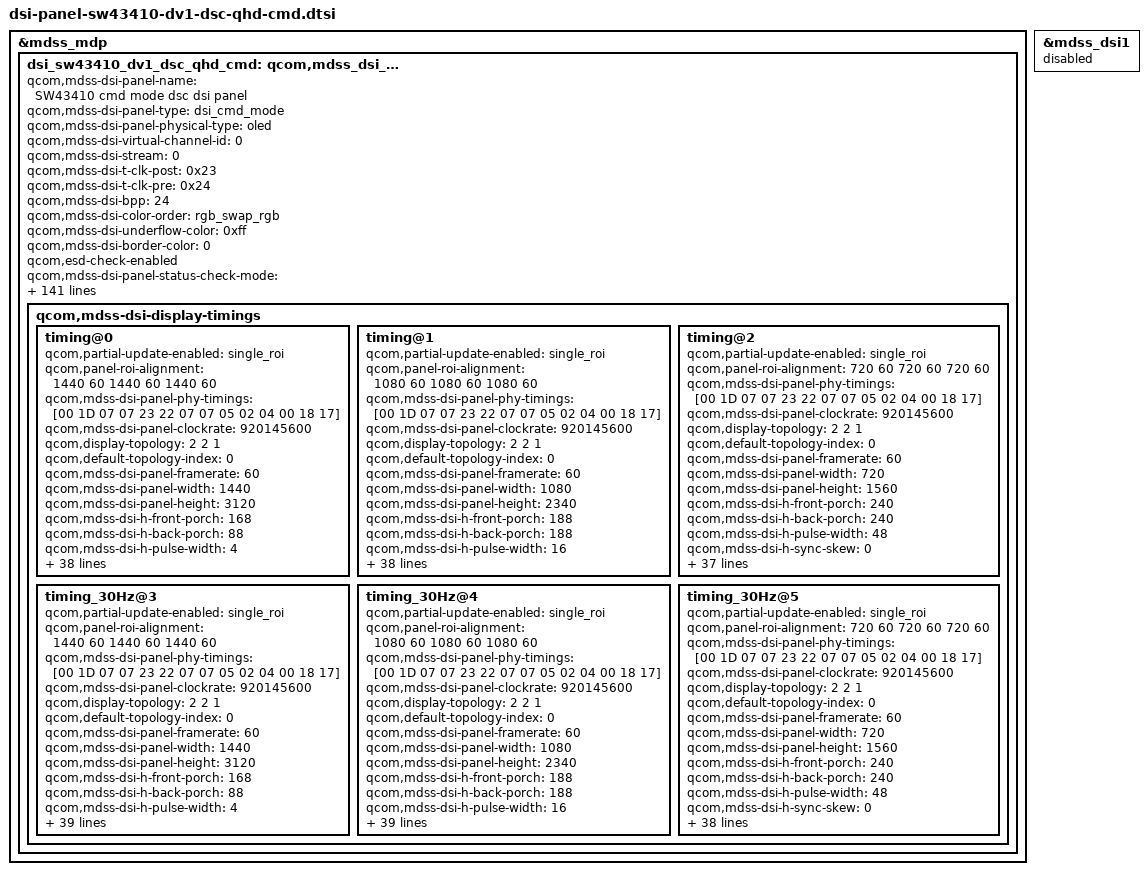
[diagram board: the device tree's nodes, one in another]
/* Copyright (c) 2014, Code Aurora Forum. All rights reserved.
 *
 * This program is free software; you can redistribute it and/or modify
 * it under the terms of the GNU General Public License version 2 and
 * only version 2 as published by the Free Software Foundation.
 *
 * This program is distributed in the hope that it will be useful,
 * but WITHOUT ANY WARRANTY; without even the implied warranty of
 * MERCHANTABILITY or FITNESS FOR A PARTICULAR PURPOSE.  See the
 * GNU General Public License for more details.
 */

&mdss_mdp {
    dsi_sw43410_dv1_dsc_qhd_cmd: qcom,mdss_dsi_sw43410_dv1_dsc_qhd_cmd {
        qcom,mdss-dsi-panel-name = "SW43410 cmd mode dsc dsi panel";
		qcom,mdss-dsi-panel-type = "dsi_cmd_mode";
		qcom,mdss-dsi-panel-physical-type = "oled";
		qcom,mdss-dsi-virtual-channel-id = <0>;
		qcom,mdss-dsi-stream = <0>;
		qcom,mdss-dsi-t-clk-post = <0x23>;
		qcom,mdss-dsi-t-clk-pre = <0x24>;
		qcom,mdss-dsi-bpp = <24>;
		qcom,mdss-dsi-color-order = "rgb_swap_rgb";
		qcom,mdss-dsi-underflow-color = <0xff>;
		qcom,mdss-dsi-border-color = <0>;
		qcom,esd-check-enabled;
		qcom,mdss-dsi-panel-status-check-mode = "te_signal_check";
		qcom,mdss-dsi-traffic-mode = "burst_mode";
		qcom,mdss-dsi-lane-map = "lane_map_0123";
		qcom,mdss-dsi-bllp-eof-power-mode;
		qcom,mdss-dsi-bllp-power-mode;
		qcom,mdss-dsi-lane-0-state;
		qcom,mdss-dsi-lane-1-state;
		qcom,mdss-dsi-lane-2-state;
		qcom,mdss-dsi-lane-3-state;
		qcom,mdss-dsi-reset-sequence = <1 10>, <0 2>, <1 10>;
		lge,mdss-iris3-reset-sequence = <1 20>, <0 20>, <1 20>;
		qcom,mdss-dsi-dma-trigger = "trigger_sw";
		qcom,mdss-dsi-mdp-trigger = "none";
		qcom,mdss-dsi-te-pin-select = <1>;
		qcom,mdss-dsi-wr-mem-start = <0x2c>;
		qcom,mdss-dsi-wr-mem-continue = <0x3c>;
		qcom,mdss-dsi-te-dcs-command = <1>;
		qcom,mdss-dsi-te-check-enable;
		qcom,mdss-dsi-te-using-te-pin;
		qcom,mdss-dsi-lp11-init;
		qcom,mdss-dsi-tx-eot-append;
		//qcom,ulps-enabled;
		//qcom,mdss-dsi-force-clock-lane-hs;

		qcom,mdss-dsi-panel-hdr-enabled;
		qcom,mdss-dsi-panel-hdr-color-primaries = <14880 15935 32435 16555 14945 30910 7790 3415>;
		qcom,mdss-dsi-panel-peak-brightness = <5643000>;		/* max. 500nits */
		qcom,mdss-dsi-panel-blackness-level = <6134>;
		qcom,dynamic-mode-switch-enabled;
		qcom,dynamic-mode-switch-type = "dynamic-resolution-switch-immediate";
		lge,drs-mngr-enabled;
		lge,drs-mngr-internal-pps-switch-enabled;
		lge,use-ambient;
		lge,aod-interface-data = "partial", "partial", "partial";

		lge,use-color-manager;
		lge,color-manager-default-status = <1>;
		lge,mdss-dsi-color-manager-mode-table = <3 1>, <0 1>, <2 1>, <1 1>;
		lge,true-view-supported;

		lge,mdss-dsi-wb-default-command = [
			15 00 00 00 00 00 02 B0 55
			39 00 00 00 00 00 21 EC 3F 03 01 56 AB FC 03 00 55 AA FC 03 00 55 AA FC 00 FF 40 80 C0 00 40 80 C0 00 40 80 C0 00 40 80
			39 00 00 00 00 00 21 ED C0 00 ED 3F 7E BD FB 3A 79 B8 F7 36 75 B4 F2 31 70 AF 00 D0 3D 7A B7 F4 31 6E AB E8 26 63 A0 DD
			39 00 00 00 00 00 04 EE 1A 57 94
			15 01 00 00 00 00 02 B0 CA
		];
		lge,mdss-dsi-wb-default-command-state = "dsi_hs_mode";

		lge,digital-gamma-cmds-dummy = [
			15 00 00 00 00 00 02 B0 55
			39 00 00 00 00 00 21 EC 3F 03 01 56 AB FC 03 00 55 AA FC 03 00 55 AA FC 00 FF 40 80 C0 00 40 80 C0 00 40 80 C0 00 40 80
			39 00 00 00 00 00 21 ED C0 00 ED 3F 7E BD FB 3A 79 B8 F7 36 75 B4 F2 31 70 AF 00 D0 3D 7A B7 F4 31 6E AB E8 26 63 A0 DD
			39 00 00 00 00 00 04 EE 1A 57 94
			15 01 00 00 00 00 02 B0 CA
		];
		lge,digital-gamma-cmds-dummy-command = "dsi_hs_mode";

		lge,mdss-dsi-disp-ctrl-command-1 = [
			39 01 00 00 00 00 03 53 0C 30
		];
		lge,mdss-dsi-disp-ctrl-command-1-state = "dsi_hs_mode";
		lge,mdss-dsi-disp-ctrl-command-2 = [
			39 01 00 00 00 00 04 55 16 29 C0
		];
		lge,mdss-dsi-disp-ctrl-command-2-state = "dsi_hs_mode";

		lge,digital-gamma-set = [
			39 01 00 00 00 00 21 EC 3F 03 01 56 AB FC 03 00 55 AA FC 03 00 55 AA FC 00 FF 40 80 C0 00 40 80 C0 00 40 80 C0 00 40 80
			39 01 00 00 00 00 21 ED C0 00 ED 3F 7E BD FB 3A 79 B8 F7 36 75 B4 F2 31 70 AF 00 D0 3D 7A B7 F4 31 6E AB E8 26 63 A0 DD
			39 01 00 00 00 00 04 EE 1A 57 94
			39 01 00 00 00 00 21 EC 3F 03 00 55 AA FC 03 00 55 AA FC 03 01 56 AB FC 00 EB 3F 7D BC FB 3A 78 B7 F6 35 73 B2 F1 30 6E
			39 01 00 00 00 00 21 ED AD 00 F0 3F 7E BD FC 3B 7A B9 F8 38 77 B6 F5 34 73 B2 00 FF 40 80 C0 00 40 80 C0 00 40 80 C0 00
			39 01 00 00 00 00 04 EE 40 80 C0
			39 01 00 00 00 00 21 EC 3F 03 00 55 AA FC 03 00 55 AA FC 03 01 56 AB FC 00 EF 3F 7E BD FC 3B 7A B9 F8 37 76 B5 F4 33 72
			39 01 00 00 00 00 21 ED B1 00 F3 3F 7E BE FD 3C 7B BB FA 39 78 B8 F7 36 75 B5 00 FF 40 80 C0 00 40 80 C0 00 40 80 C0 00
			39 01 00 00 00 00 04 EE 40 80 C0
			39 01 00 00 00 00 21 EC 3F 03 00 55 AA FC 03 00 55 AA FC 03 01 56 AB FC 00 F3 3F 7E BE FD 3C 7B BB FA 39 78 B8 F7 36 75
			39 01 00 00 00 00 21 ED B5 00 F6 3F 7F BE FE 3D 7D BC FB 3B 7A BA F9 39 78 B8 00 FF 40 80 C0 00 40 80 C0 00 40 80 C0 00
			39 01 00 00 00 00 04 EE 40 80 C0
			39 01 00 00 00 00 21 EC 3F 03 00 55 AA FC 03 00 55 AA FC 03 01 56 AB FC 00 F7 3F 7F BE FE 3D 7D BC FC 3B 7B BA FA 39 79
			39 01 00 00 00 00 21 ED B8 00 F9 40 7F BF FE 3E 7E BD FD 3D 7C BC FB 3B 7B BA 00 FF 40 80 C0 00 40 80 C0 00 40 80 C0 00
			39 01 00 00 00 00 04 EE 40 80 C0
			39 01 00 00 00 00 21 EC 3F 03 00 55 AA FC 03 00 55 AA FC 03 01 56 AB FC 00 FB 40 7F BF FF 3F 7E BE FE 3E 7D BD FD 3D 7C
			39 01 00 00 00 00 21 ED BC 00 FC 40 80 BF FF 3F 7F BF FE 3E 7E BE FE 3E 7D BD 00 FF 40 80 C0 00 40 80 C0 00 40 80 C0 00
			39 01 00 00 00 00 04 EE 40 80 C0
			39 01 00 00 00 00 21 EC 3F 03 01 56 AB FC 03 01 56 AB FC 03 01 56 AB FC 00 FF 40 80 C0 00 40 80 C0 00 40 80 C0 00 40 80
			39 01 00 00 00 00 21 ED C0 00 FF 40 80 C0 00 40 80 C0 00 40 80 C0 00 40 80 C0 00 FF 40 80 C0 00 40 80 C0 00 40 80 C0 00
			39 01 00 00 00 00 04 EE 40 80 C0
			39 01 00 00 00 00 21 EC 3F 03 01 56 AB FC 03 00 55 AA FC 03 00 55 AA FC 00 FF 40 80 C0 00 40 80 C0 00 40 80 C0 00 40 80
			39 01 00 00 00 00 21 ED C0 00 FD 40 80 C0 FF 3F 7F BF FF 3F 7F BF FE 3E 7E BE 00 F9 40 7F BF FE 3E 7E BD FD 3D 7C BC FB
			39 01 00 00 00 00 04 EE 3B 7B BA
			39 01 00 00 00 00 21 EC 3F 03 01 56 AB FC 03 00 55 AA FC 03 00 55 AA FC 00 FF 40 80 C0 00 40 80 C0 00 40 80 C0 00 40 80
			39 01 00 00 00 00 21 ED C0 00 FB 40 7F BF FF 3F 7E BE FE 3E 7D BD FD 3D 7C BC 00 F3 3F 7E BE FD 3C 7B BB FA 39 78 B8 F7
			39 01 00 00 00 00 04 EE 36 75 B5
			39 01 00 00 00 00 21 EC 3F 03 01 56 AB FC 03 00 55 AA FC 03 00 55 AA FC 00 FF 40 80 C0 00 40 80 C0 00 40 80 C0 00 40 80
			39 01 00 00 00 00 21 ED C0 00 FA 40 7F BF FF 3E 7E BE FD 3D 7D BD FC 3C 7C BB 00 EE 3F 7E BD FC 3B 7A B9 F7 36 75 B4 F3
			39 01 00 00 00 00 04 EE 32 71 B0
			39 01 00 00 00 00 21 EC 3F 03 01 56 AB FC 03 00 55 AA FC 03 00 55 AA FC 00 FF 40 80 C0 00 40 80 C0 00 40 80 C0 00 40 80
			39 01 00 00 00 00 21 ED C0 00 F8 40 7F BF FE 3E 7D BD FC 3C 7C BB FB 3A 7A B9 00 E7 3E 7D BB FA 38 77 B5 F4 32 71 AF EE
			39 01 00 00 00 00 04 EE 2C 6B A9
			39 01 00 00 00 00 21 EC 3F 03 01 56 AB FC 03 00 55 AA FC 03 00 55 AA FC 00 FF 40 80 C0 00 40 80 C0 00 40 80 C0 00 40 80
			39 01 00 00 00 00 21 ED C0 00 F6 3F 7F BE FE 3D 7D BC FB 3B 7A BA F9 39 78 B8 00 E1 3E 7C BA F8 37 75 B3 F1 2F 6D AB E9
			39 01 00 00 00 00 04 EE 28 66 A4
			39 01 00 00 00 00 21 EC 3F 03 01 56 AB FC 03 00 55 AA FC 03 00 55 AA FC 00 FF 40 80 C0 00 40 80 C0 00 40 80 C0 00 40 80
			39 01 00 00 00 00 21 ED C0 00 F3 3F 7E BE FD 3C 7B BB FA 39 78 B8 F7 36 75 B5 00 DB 3E 7B B9 F7 35 72 B0 EE 2C 69 A7 E5
			39 01 00 00 00 00 04 EE 23 60 9E
			39 01 00 00 00 00 21 EC 3F 03 01 56 AB FC 03 00 55 AA FC 03 00 55 AA FC 00 FF 40 80 C0 00 40 80 C0 00 40 80 C0 00 40 80
			39 01 00 00 00 00 21 ED C0 00 F0 3F 7E BD FC 3B 7A B9 F8 38 77 B6 F5 34 73 B2 00 D5 3D 7B B8 F5 33 70 AE EB 28 66 A3 E0
			39 01 00 00 00 00 04 EE 1E 5B 99
			39 01 00 00 00 00 21 EC 3F 03 01 56 AB FC 03 00 55 AA FC 03 00 55 AA FC 00 FF 40 80 C0 00 40 80 C0 00 40 80 C0 00 40 80
			39 01 00 00 00 00 21 ED C0 00 ED 3F 7E BD FB 3A 79 B8 F7 36 75 B4 F2 31 70 AF 00 D0 3D 7A B7 F4 31 6E AB E8 26 63 A0 DD
			39 01 00 00 00 00 04 EE 1A 57 94
			39 01 00 00 00 00 21 EC 3F 03 01 56 AB FC 03 00 55 AA FC 03 00 55 AA FC 00 FF 40 80 C0 00 40 80 C0 00 40 80 C0 00 40 80
			39 01 00 00 00 00 21 ED C0 00 EA 3F 7D BC FB 39 78 B7 F5 34 73 B2 F0 2F 6E AC 00 C8 3D 79 B6 F2 2F 6B A8 E4 21 5E 9A D7
			39 01 00 00 00 00 04 EE 13 50 8C
			39 01 00 00 00 00 21 EC 3F 03 01 56 AB FC 03 00 55 AA FC 03 00 55 AA FC 00 FF 40 80 C0 00 40 80 C0 00 40 80 C0 00 40 80
			39 01 00 00 00 00 21 ED C0 00 E8 3F 7D BC FA 39 77 B6 F4 33 72 B0 EF 2D 6C AA 00 C2 3C 78 B5 F1 2D 69 A5 E1 1E 5A 96 D2
			39 01 00 00 00 00 04 EE 0E 4B 87
			39 01 00 00 00 00 21 EC 3F 03 01 56 AB FC 03 00 55 AA FC 03 00 55 AA FC 00 FF 40 80 C0 00 40 80 C0 00 40 80 C0 00 40 80
			39 01 00 00 00 00 21 ED C0 00 E3 3E 7C BB F9 37 75 B4 F2 30 6E AD EB 29 67 A6 00 BA 3C 77 B3 EF 2A 66 A2 DD 19 55 91 CC
			39 01 00 00 00 00 04 EE 08 44 7F
			39 01 00 00 00 00 21 EC 3F 03 01 56 AB FC 03 00 55 AA FC 03 00 55 AA FC 00 FF 40 80 C0 00 40 80 C0 00 40 80 C0 00 40 80
			39 01 00 00 00 00 21 ED C0 00 E0 3E 7C BA F8 36 74 B2 F0 2F 6D AB E9 27 65 A3 00 B3 3B 76 B2 ED 28 63 9F DA 15 50 8C C7
			39 01 00 00 00 00 04 EE 02 3D 79
			39 01 00 00 00 00 21 EC 3F 03 01 56 AB FC 03 00 55 AA FC 03 00 55 AA BC 00 FF 40 80 C0 00 40 80 C0 00 40 80 C0 00 40 80
			39 01 00 00 00 00 21 ED C0 00 DD 3E 7C BA F7 35 73 B1 EF 2D 6B A9 E6 24 62 A0 00 AD 3B 76 B1 EB 26 61 9C D7 12 4D 88 C2
			39 01 00 00 00 00 04 EE FD 38 73
			39 01 00 00 00 00 21 EC 3F 03 01 56 AB FC 03 00 55 AA FC 03 00 55 AA BC 00 FF 40 80 C0 00 40 80 C0 00 40 80 C0 00 40 80
			39 01 00 00 00 00 21 ED C0 00 DA 3E 7B B9 F7 34 72 B0 ED 2B 69 A7 E4 22 60 9D 00 A6 3A 75 AF EA 24 5F 99 D3 0E 48 83 BD
			39 01 00 00 00 00 04 EE F8 32 6C
			39 01 00 00 00 00 21 EC 3F 03 01 56 AB FC 03 00 55 AA FC 03 00 55 AA BC 00 FF 40 80 C0 00 40 80 C0 00 40 80 C0 00 40 80
			39 01 00 00 00 00 21 ED C0 00 D7 3D 7B B8 F6 33 71 AE EC 29 67 A4 E2 1F 5D 9A 00 9F 3A 74 AE E8 22 5C 96 D0 0A 44 7E B8
			39 01 00 00 00 00 04 EE F2 2C 66
			39 01 00 00 00 00 21 EC 3F 03 00 55 AA FC 03 00 55 AA FC 03 00 55 AA BC 00 FD 40 80 C0 FF 3F 7F BF FF 3F 7F BF FE 3E 7E
			39 01 00 00 00 00 21 ED BE 00 D3 3D 7A B8 F5 32 6F AD EA 27 64 A2 DF 1C 59 97 00 98 3A 73 AD E6 20 59 93 CC 06 40 79 B3
			39 01 00 00 00 00 04 EE EC 26 5F
			39 01 00 00 00 00 21 EC 3F 03 00 55 AA FC 03 00 55 AA FC 03 00 55 AA BC 00 FA 40 7F BF FF 3E 7E BE FD 3D 7D BD FC 3C 7C
			39 01 00 00 00 00 21 ED BB 00 CF 3D 7A B7 F4 31 6E AB E8 25 62 9F DC 19 56 93 00 91 39 72 AB E4 1E 57 90 C9 02 3B 74 AD
			39 01 00 00 00 00 04 EE E7 20 59
			39 01 00 00 00 00 21 EC 3F 03 00 55 AA FC 03 00 55 AA FC 03 00 55 6A BC 00 F8 40 7F BF FE 3E 7D BD FC 3C 7C BB FB 3A 7A
			39 01 00 00 00 00 21 ED B9 00 CB 3D 79 B6 F3 30 6C A9 E6 23 5F 9C D9 16 52 8F 00 88 39 71 AA E2 1B 53 8C C4 FD 36 6E A7
			39 01 00 00 00 00 04 EE DF 18 50
			39 01 00 00 00 00 21 EC 3F 03 00 55 AA FC 03 00 55 AA FC 03 00 55 6A BC 00 F5 3F 7F BE FD 3D 7C BC FB 3A 7A B9 F8 38 77
			39 01 00 00 00 00 21 ED B7 00 C7 3C 79 B5 F2 2E 6B A7 E4 20 5D 99 D6 12 4F 8B 00 81 38 70 A8 E0 19 51 89 C1 F9 31 69 A1
			39 01 00 00 00 00 04 EE DA 12 4A
			39 01 00 00 00 00 21 EC 3F 03 00 55 AA FC 03 00 55 AA FC 03 00 55 6A BC 00 F3 3F 7E BE FD 3C 7B BB FA 39 78 B8 F7 36 75
			39 01 00 00 00 00 21 ED B5 00 C3 3C 78 B5 F1 2D 69 A6 E2 1E 5A 97 D3 0F 4B 88 00 7A 38 6F A7 DF 16 4E 86 BD F5 2D 64 9C
			39 01 00 00 00 00 04 EE D4 0C 43
			39 01 00 00 00 00 21 EC 3F 03 00 55 AA FC 03 00 55 AA FC 03 00 55 6A BC 00 EF 3F 7E BD FC 3B 7A B9 F8 37 76 B5 F4 33 72
			39 01 00 00 00 00 21 ED B1 00 C1 3C 78 B4 F0 2D 69 A5 E1 1D 59 95 D1 0E 4A 86 00 70 37 6E A5 DC 13 4A 81 B8 EF 27 5E 95
			39 01 00 00 00 00 04 EE CC 03 3A
			39 01 00 00 00 00 21 EC 3F 03 00 55 AA FC 03 00 55 AA FC 03 00 55 6A AC 00 EC 3F 7E BC FB 3A 79 B8 F6 35 74 B3 F2 31 6F
			39 01 00 00 00 00 21 ED AE 00 BA 3C 77 B3 EF 2A 66 A2 DD 19 55 91 CC 08 44 7F 00 67 36 6D A3 DA 10 47 7D B4 EA 21 57 8E
			39 01 00 00 00 00 04 EE C4 FB 31
			39 01 00 00 00 00 21 EC 3F 03 00 55 AA FC 03 00 55 AA FC 03 00 55 6A AC 00 E7 3E 7D BB FA 38 77 B5 F4 32 71 AF EE 2C 6B
			39 01 00 00 00 00 21 ED A9 00 B4 3B 77 B2 ED 29 64 9F DA 16 51 8C C8 03 3E 7A 00 5C 36 6C A1 D7 0D 43 79 AE E4 1A 50 86
			39 01 00 00 00 00 04 EE BB F1 27
			39 01 00 00 00 00 21 EC 3F 03 00 55 AA FC 03 00 55 AA BC 03 00 55 6A AC 00 E3 3E 7C BB F9 37 75 B4 F2 30 6E AD EB 29 67
			39 01 00 00 00 00 21 ED A6 00 AE 3B 76 B1 EC 27 62 9D D7 12 4D 88 C3 FE 39 74 00 52 35 6A A0 D5 0A 3F 74 A9 DF 14 49 7E
			39 01 00 00 00 00 04 EE B3 E8 1E
		];
		lge,digital-gamma-command-state = "dsi_hs_mode";

		lge,blmap = <
			1
			7 7 7 7 7 7 7 7 7 7 7 8 8 9 9 10 10 10 11 11
			12 12 13 13 13 14 14 15 15 15 16 16 17 17 18 18 18 19 19 20
			20 21 21 22 22 22 23 23 24 24 25 25 25 26 26 27 27 28 28 29
			29 31 32 34 36 38 39 41 43 44 46 48 50 51 53 55 56 58 60 61
			63 65 67 68 70 72 73 75 77 79 80 82 84 86 87 89 91 93 94 96
			98 100 101 103 105 107 108 110 113 116 119 122 124 127 130 133 136 139 142 145
			148 150 153 156 159 162 165 168 171 173 176 179 182 185 188 191 194 197 200 203
			206 209 212 215 217 220 223 226 229 232 235 238 241 244 247 250 253 256 259 264
			268 273 278 282 287 291 296 301 305 310 315 319 324 328 333 338 342 347 352 356
			361 365 370 375 379 384 389 393 398 402 407 412 416 421 426 430 435 439 444 449
			453 458 463 467 472 476 481 487 493 499 505 511 517 522 528 534 540 546 552 558
			564 570 576 582 588 593 599 605 611 617 623 629 635 642 648 655 661 668 674 680
			687 693 700 706 713 719 726 732 738 745 751 758 764 771 777 777 777 777 777 777
			777 777 778 778 778 778 778 778 778 778 778 778 778 778 778 778 778 778 779 779
			779 779 779 779 779 779 780 782 783 784 785 787 788 789 792 795 797 800 803 806
			808 811 813 815 817 818 820 822 824 826 828 829 831 833 835 837 839 840 842 844
			848 852 855 859 863 867 870 874 878 882 885 889 893 898 902 907 911 916 920 925
			929 934 938 943 947 952 956 959 963 967 971 974 978 982 986 989 993 997 1001 1004
			1008 1012 1016 1019 1023
		>;
		lge,blmap-ve = <
			1
			7 7 7 7 7 7 7 7 7 7 7 7 7 8 8 8 8 8 8 9
			9 9 9 9 9 9 10 10 10 10 10 10 11 11 11 11 12 13 14 15
			16 17 19 20 21 22 23 24 25 26 27 28 29 30 32 33 34 35 36 37
			38 40 42 44 45 47 49 51 53 55 56 58 60 62 64 66 67 69 71 73
			75 77 80 83 82 85 88 90 93 96 99 102 105 107 110 113 116 119 122 124
			127 130 133 136 139 141 144 147 150 154 157 160 164 167 170 174 177 180 184 187
			191 194 197 201 204 207 211 214 217 221 224 227 231 234 238 243 247 251 255 260
			264 267 272 276 280 284 289 293 297 302 306 310 314 319 323 327 332 336 341 346
			351 357 362 367 372 377 383 388 393 398 404 409 414 419 424 430 435 440 445 450
			456 461 466 471 477 482 487 492 498 503 508 513 519 524 529 534 540 545 550 555
			561 566 571 576 582 587 592 599 606 613 620 627 634 641 648 655 662 669 676 683
			690 697 704 711 718 725 732 739 746 753 760 767 776 784 793 802 810 819 828 837
			845 854 863 871 880 889 897 906 915 924 932 941 950 958 967 967 967 967 967 967
			967 967 967 967 967 967 967 967 967 967 967 967 967 967 967 967 967 967 967 967
			967 967 967 967 967 967 967 968 968 968 968 969 969 969 970 970 971 971 972 972
			973 973 974 974 975 976 977 977 978 979 980 980 981 982 982 983 984 985 985 986
			986 987 987 988 988 989 989 990 990 991 991 992 992 993 994 995 996 997 998 999
			1000 1001 1002 1003 1004 1005 1006 1007 1008 1009 1010 1011 1012 1013 1014 1014 1015 1016 1017 1018
			1019 1020 1021 1022 1023
		>;
		lge,blmap-ex = <
			1
			10 10 10 10 10 10 10 10 127 129 131 133 135 137 139 142 144 146 148 150
			152 154 156 158 160 162 164 166 168 171 173 175 177 179 181 183 189 194 200 205
			211 216 222 227 233 238 244 249 255 261 266 272 277 283 288 294 299 305 310 316
			321 327 333 338 344 349 355 360 366 371 377 382 388 393 399 407 415 423 431 439
			447 455 463 471 479 487 495 503 511 519 527 535 543 551 559 567 575 581 587 594
			600 606 612 619 625 631 637 643 650 656 662 668 675 681 687 695 704 712 721 729
			738 746 754 763 771 780 788 796 805 813 822 830 839 847 847 847 847 847 847 847
			856 866 875 884 893 903 912 921 930 940 949 958 967 977 986 995 1004 1014 1023 1023
			1023 1023 1023 1023 1023 1023 1023 1023 1023 1023 1023 1023 1023 1023 1023 1023 1023 1023 1023 1023
			1023 1023 1023 1023 1023 1023 1023 1023 1023 1023 1023 1023 1023 1023 1023 1023 1023 1023 1023 1023
			1023 1023 1023 1023 1023 1023 1023 1023 1023 1023 1023 1023 1023 1023 1023 1023 1023 1023 1023 1023
			1023 1023 1023 1023 1023 1023 1023 1023 1023 1023 1023 1023 1023 1023 1023 1023 1023 1023 1023 1023
			1023 1023 1023 1023 1023 1023 1023 1023 1023 1023 1023 1023 1023 1023 1023
		>;
		lge,blmap-hdr = <
			1
			7 7 7 7 7 7 7 7 7 7 7 7 7 8 8 8 8 8 8 9
			9 9 9 9 9 9 10 10 10 10 10 10 11 11 11 11 12 13 14 15
			16 17 18 19 20 21 22 23 23 24 25 26 27 28 29 30 31 32 33 34
			35 37 39 40 42 44 46 47 49 51 53 54 56 58 60 61 63 65 67 68
			70 72 75 77 77 79 82 84 87 89 92 94 97 99 102 104 107 109 112 114
			117 119 122 124 127 129 132 134 137 140 143 146 149 152 156 159 162 165 168 171
			174 177 180 183 186 189 192 196 199 202 205 208 211 214 218 222 226 230 234 238
			242 245 249 253 257 262 266 270 274 278 282 286 290 294 298 302 306 310 315 320
			324 329 333 338 342 347 351 356 360 365 370 374 379 383 388 392 397 401 406 410
			415 419 424 429 434 439 445 450 455 460 465 470 475 480 486 491 496 501 506 511
			516 521 527 532 537 542 547 553 559 565 571 577 583 589 595 601 607 613 619 624
			630 636 642 648 654 660 666 672 678 684 690 696 704 711 719 727 734 742 750 757
			765 773 780 788 795 803 811 818 826 834 841 849 857 864 872 872 872 872 872 872
			872 872 872 872 872 872 872 872 872 872 873 873 873 873 873 873 873 873 873 873
			873 873 873 873 873 873 874 875 875 876 877 878 878 879 881 884 886 888 890 893
			895 897 898 899 901 902 903 904 905 906 908 909 910 911 912 913 914 916 917 918
			920 922 924 926 928 930 932 934 936 938 940 942 944 947 950 952 955 958 961 963
			966 969 972 974 977 980 982 985 987 989 991 994 996 998 1000 1003 1005 1007 1009 1012
			1014 1016 1018 1021 1023
		>;

		qcom,mdss-pan-physical-width-dimension = <65>;
		qcom,mdss-pan-physical-height-dimension = <140>;

		lge,update-pps-in-lp-mode;

		lge,mdss-dsi-nolp-command = [
			15 01 00 00 00 00 02 B0 AC
			39 01 00 00 00 00 43 E7 0F FF 00 0F FF 00 0F FF 00 0F FF 00 0F FF 00 0F FF 00 0F FF 00 0F FF 00 0F FF 00 0F FF 00 0F FF 00 0F FF 00 0F FF 00 0F FF 00 0F FF 00 0F FF 00 0F FF 00 0F FF 00 0F FF 00 0F FF 00 0F FF 00 0F FF 00
			39 01 00 00 00 00 1F E8 0F FF 00 0F FF 00 0F FF 00 0F FF 00 0F FF 00 0F FF 00 0F FF 00 0F FF 00 0F FF 00 0F FF 00
			15 01 00 00 00 00 02 EB 6F
			39 01 00 00 00 00 05 30 00 00 0C 2F
			39 01 00 00 00 00 05 31 00 00 05 9F
			39 01 00 00 00 00 07 55 16 29 C0 04 78 DF
			39 01 00 00 00 00 0B C3 10 15 1F 12 AD 4D B1 51 BD 1D
			39 01 00 00 28 00 05 CB 80 5C 07 11
			05 01 00 00 00 00 01 13
			39 01 00 00 78 00 0D B4 2D 02 00 22 21 21 21 0A 10 87 12 00
			39 01 00 00 00 00 43 E7 30 00 10 30 00 10 30 00 10 30 00 10 30 00 10 11 3A D7 11 88 89 11 D7 3A 02 25 EC 02 74 9D 02 C2 4F 30 00 10 30 00 10 30 00 10 30 00 10 30 00 10 11 3A D7 11 88 89 11 D7 3A 02 25 EC 02 74 9D 02 C2 4F
			39 01 00 00 14 00 1F E8 20 9D 74 11 3A D7 03 01 10 47 5E EA B1 0E 3A 20 9D 74 11 3A D7 03 01 10 47 5E EA B1 0E 3A
		];
		lge,mdss-dsi-nolp-command-state = "dsi_lp_mode";

		lge,mdss-dsi-aod-area-command = [
			15 01 00 00 00 00 02 B0 AC
			39 01 00 00 00 00 05 30 00 00 0C 2F
		];
		lge,mdss-dsi-aod-area-command-state = "dsi_lp_mode";

		lge,mdss-dsi-lp2-command = [
			15 01 00 00 00 00 02 B0 AC
			39 01 00 00 00 00 43 E7 0F FF 00 0F FF 00 0F FF 00 0F FF 00 0F FF 00 0F FF 00 0F FF 00 0F FF 00 0F FF 00 0F FF 00 0F FF 00 0F FF 00 0F FF 00 0F FF 00 0F FF 00 0F FF 00 0F FF 00 0F FF 00 0F FF 00 0F FF 00 0F FF 00 0F FF 00
			39 01 00 00 00 00 1F E8 0F FF 00 0F FF 00 0F FF 00 0F FF 00 0F FF 00 0F FF 00 0F FF 00 0F FF 00 0F FF 00 0F FF 00
			15 01 00 00 00 00 02 EB EF
			39 01 00 00 00 00 03 B4 2F 00
			39 01 00 00 00 00 15 BF 30 0F 0F 11 22 00 00 00 00 00 00 00 00 03 03 33 00 01 00 20
			39 01 00 00 00 00 03 53 0C 30
			39 01 00 00 00 00 07 55 16 29 C9 04 78 DF
			39 01 00 00 00 00 0B C3 10 15 1F 12 AD 4D B1 51 BD 1D
			39 01 00 00 00 00 03 C1 01 48
			39 01 00 00 00 00 05 CA 08 99 10 0F
			39 01 00 00 1E 00 05 CB 80 5C 07 07
			39 01 00 00 00 00 03 51 00 01
			05 01 00 00 64 00 01 12
			39 01 00 00 00 00 43 E7 30 00 10 30 00 10 30 00 10 30 00 10 30 00 10 11 3A D7 11 88 89 11 D7 3A 02 25 EC 02 74 9D 02 C2 4F 30 00 10 30 00 10 30 00 10 30 00 10 30 00 10 11 3A D7 11 88 89 11 D7 3A 02 25 EC 02 74 9D 02 C2 4F
			39 01 00 00 14 00 1F E8 20 9D 74 11 3A D7 03 01 10 47 5E EA B1 0E 3A 20 9D 74 11 3A D7 03 01 10 47 5E EA B1 0E 3A
		];
		lge,mdss-dsi-lp2-command-state = "dsi_lp_mode";

		/* Panel Error Detection */
		lge,use-panel-err-detect;
		interrupt-parent = <&tlmm>;
		interrupts = <36 0x2001>; /*IRQF_ONESHOT | IRQF_TRIGGER_RISING*/
		lge,err-detect-gpio = <&tlmm 36 0x2001>; /* IRQF_ONESHOT | IRQF_TRIGGER_RISING */

		lge,memory-error-detect-command = [
			15 01 00 00 10 00 02 B0 AC
			39 01 00 00 00 00 05 CE 22 10 00 00
			15 01 00 00 10 00 02 B0 CA
		];
		lge,memory-error-detect-command-state = "dsi_hs_mode";

		lge,esd-detect-command = [
			15 01 00 00 10 00 02 B0 AC
			39 01 00 00 00 00 05 CE 00 00 00 00
			15 01 00 00 10 00 02 B0 CA
		];
		lge,esd-detect-command-state = "dsi_hs_mode";
		lge,line-defect-detect-command = [
			15 01 00 00 10 00 02 B0 AC
			39 01 00 00 00 00 05 CE 00 16 00 00
			15 01 00 00 10 00 02 B0 CA
		];
		lge,line-defect-detect-command-state = "dsi_hs_mode";

		lge,use-line-detect;
		lge,detect-vert-line-restore-command = [
			15 01 00 00 00 00 02 B0 AC
			39 01 00 00 00 00 19 C2 70 8A 0A 0A 33 8C 8C 33 8C 8C 0A ED AD 63 23 00 00 64 24 43 64 15 15 64
			39 01 00 00 00 00 12 C3 10 15 1F 12 AD 4D B1 51 BD 1D 22 03 C8 20 83 0C 17
			15 01 00 00 00 00 02 B0 CA
		];
		lge,detect-vert-line-restore-command-state = "dsi_hs_mode";
		lge,detect-black-vert-line-command = [
			15 01 00 00 00 00 02 B0 AC
			39 01 00 00 00 00 19 C2 70 93 0A 0A 33 96 8C 33 8C 8C 0A ED AD 63 23 00 00 64 24 43 64 15 15 64
			39 01 00 00 00 00 12 C3 10 15 15 12 AD 4D BF 51 BD 1D 22 02 C8 20 83 0C 17
			15 01 00 00 00 00 02 B0 CA
		];
		lge,detect-black-vert-line-command-state = "dsi_hs_mode";
		lge,detect-white-vert-line-command = [
			15 01 00 00 00 00 02 B0 AC
			39 01 00 00 00 00 19 C2 70 80 0A 0A 33 82 8C 33 8C 8C 0A ED AD 63 23 00 00 64 24 43 64 15 15 64
			39 01 00 00 00 00 12 C3 10 15 15 12 AD 4D BF 51 BD 1D 22 02 C8 20 83 0C 17
			15 01 00 00 00 00 02 B0 CA
		];
		lge,detect-white-vert-line-command-state = "dsi_hs_mode";

		lge,mdss-dsi-saturation-command = [
			15 00 00 00 00 00 02 B0 55
			39 00 00 00 00 00 21 CC 88 0A 4B 6C FF 58 60 60 80 67 70 80 7A 74 6E 60 79 65 60 60 68 74 67 87 7A 74 6A 60 7A 7A 5C 6C
			39 00 00 00 00 00 21 CD 6C 80 80 7A 79 75 6A 68 7C 83 83 83 83 83 83 83 83 83 83 83 83 83 83 83 83 83 83 83 83 83 83 83
			15 01 00 00 00 00 02 B0 CA
		];
		lge,mdss-dsi-saturation-command-state = "dsi_hs_mode";

		lge,mdss-dsi-hue-command = [
			15 00 00 00 00 00 02 B0 55
			39 00 00 00 00 00 21 CE 83 83 83 83 83 83 83 7A 83 83 83 83 83 7F 7F 7F 7F 7F 7F 7F 7E 7E 7E 7F 7F F4 00 06 02 01 06 E4
			39 00 00 00 00 00 21 CF EF EF EF F6 06 00 0A 81 D3 FF 4C 50 48 48 4C 50 50 4A 45 4E 4C 52 54 54 54 58 58 68 65 6B 53 5B
			15 01 00 00 00 00 02 B0 CA
		];
		lge,mdss-dsi-hue-command-state = "dsi_hs_mode";

		lge,mdss-dsi-sharpness-command = [
			15 00 00 00 00 00 02 B0 55
			39 00 00 00 00 00 1F DD FB F8 40 10 07 06 04 04 20 06 30 20 03 80 04 01 02 58 E0 00 8F 00 FF 7F A0 00 E0 08 C0 10
			15 01 00 00 00 00 02 B0 CA
		];
		lge,mdss-dsi-sharpness-command-state = "dsi_hs_mode";

		// Sports Mode : 8200K
		lge,mdss-dsi-cm-sports = [
			15 00 00 00 00 00 02 B0 55
			39 00 00 00 00 00 21 EC 3F 03 00 55 AA FC 03 00 55 AA FC 03 01 56 AB FC 00 EB 3F 7D BC FB 3A 78 B7 F6 35 73 B2 F1 30 6E
			39 00 00 00 00 00 21 ED AD 00 F0 3F 7E BD FC 3B 7A B9 F8 38 77 B6 F5 34 73 B2 00 FF 40 80 C0 00 40 80 C0 00 40 80 C0 00
			39 00 00 00 00 00 04 EE 40 80 C0
			15 01 00 00 00 00 02 B0 CA
		];
		lge,mdss-dsi-cm-sports-state = "dsi_hs_mode";

		// Game Mode : 7800K
		lge,mdss-dsi-cm-game = [
			15 00 00 00 00 00 02 B0 55
			39 00 00 00 00 00 21 CC 88 0A 4B 6C FF 61 6A 6A 8D 71 7B 95 86 83 79 6A 85 6F 6A 6A 72 84 71 95 86 81 75 6A 86 7A 5C 6C
			39 00 00 00 00 00 21 CD 6C 80 80 80 7A 78 6A 68 7C 83 83 83 83 83 83 83 83 83 83 83 83 83 83 83 83 83 83 83 83 83 83 83
			39 00 00 00 00 00 21 EC 3F 03 00 55 AA FC 03 00 55 AA FC 03 01 56 AB FC 00 F3 3F 7E BE FD 3C 7B BB FA 39 78 B8 F7 36 75
			39 00 00 00 00 00 21 ED B5 00 F6 3F 7F BE FE 3D 7D BC FB 3B 7A BA F9 39 78 B8 00 FF 40 80 C0 00 40 80 C0 00 40 80 C0 00
			39 00 00 00 00 00 04 EE 40 80 C0
			15 01 00 00 00 00 02 B0 CA
		];
		lge,mdss-dsi-cm-game-state = "dsi_hs_mode";

		lge,mdss-dsi-irc-command = [
			15 00 00 00 00 00 02 B0 55
			15 00 00 00 00 00 02 E2 FC
			15 01 00 00 00 00 02 B0 CA
		];
		lge,mdss-dsi-irc-command-state = "dsi_lp_mode";

		lge,use-ace-ctrl;
		lge,default-ace-mode = <3>;
		lge,mdss-dsi-ace-tune-command = [
			15 00 00 00 00 00 02 B0 55
			39 00 00 00 00 00 0A C1 C0 05 00 C0 05 00 C0 05 00
			39 00 00 00 00 00 21 C2 98 FF F9 F3 EE E8 E3 DD D8 D2 CD C7 C2 BC B7 B1 AC A6 A1 9B 96 90 8B 85 80 80 80 80 80 80 80 80
			15 01 00 00 00 00 02 B0 CA
		];
		lge,mdss-dsi-ace-restore-command = [
			15 00 00 00 00 00 02 B0 55
			39 00 00 00 00 00 0A C1 FF 07 00 FF 07 00 FF 07 00
			39 00 00 00 00 00 21 C2 B8 A6 A6 A6 A5 A4 A1 9F 9C 98 94 92 8F 8D 8A 88 85 84 83 82 81 81 80 80 80 80 80 80 80 80 80 80
			15 01 00 00 00 00 02 B0 CA
		];
		lge,mdss-dsi-ace-cmmand-state = "dsi_lp_mode";

		lge,mdss-dsi-ve-on-command = [
			15 00 00 00 00 00 02 B0 55
			39 00 00 00 00 00 0A C1 C3 05 00 C3 05 00 C3 05 00
			15 01 00 00 00 00 02 B0 CA
		];
		lge,mdss-dsi-ve-on-command-state = "dsi_hs_mode";

		lge,mdss-dsi-ve-off-command = [
			15 00 00 00 00 00 02 B0 55
			39 00 00 00 00 00 0A C1 FF 07 00 FF 07 00 FF 07 00
			15 01 00 00 00 00 02 B0 CA
		];
		lge,mdss-dsi-ve-off-command-state = "dsi_hs_mode";

		qcom,mdss-dsi-display-timings {
			timing@0{
				qcom,partial-update-enabled = "single_roi";
				qcom,panel-roi-alignment = <1440 60 1440 60 1440 60>;
				qcom,mdss-dsi-panel-phy-timings = [00 1D 07 07 23 22 07 07 05 02 04 00 18 17];
				qcom,mdss-dsi-panel-clockrate = <920145600>;
				qcom,display-topology = <2 2 1>;
				qcom,default-topology-index = <0>;
				qcom,mdss-dsi-panel-framerate = <60>;
				qcom,mdss-dsi-panel-width = <1440>;
				qcom,mdss-dsi-panel-height = <3120>;
				qcom,mdss-dsi-h-front-porch = <168>;
				qcom,mdss-dsi-h-back-porch = <88>;
				qcom,mdss-dsi-h-pulse-width = <4>;
				qcom,mdss-dsi-h-sync-skew = <0>;
				qcom,mdss-dsi-v-back-porch = <10>;
				qcom,mdss-dsi-v-front-porch = <9>;
				qcom,mdss-dsi-v-pulse-width = <1>;
				qcom,mdss-dsi-h-left-border = <0>;
				qcom,mdss-dsi-h-right-border = <0>;
				qcom,mdss-dsi-v-top-border = <0>;
				qcom,mdss-dsi-v-bottom-border = <0>;
				qcom,mdss-dsi-h-sync-pulse = <0>;
				qcom,mdss-mdp-transfer-time-us = <15000>;

				qcom,mdss-dsi-on-command = [
					07 01 00 00 00 00 02 11 00
					15 01 00 00 00 00 02 B0 AC
					15 01 00 00 00 00 02 3D 08
					39 01 00 00 00 00 07 F8 01 49 0C FF 7F 04
					15 01 00 00 00 00 02 26 01
					15 01 00 00 00 00 02 35 00
					15 01 00 00 00 00 02 B0 CA
					05 01 00 00 3C 00 01 11
					39 01 00 00 00 00 03 51 00 01
					39 01 00 00 00 00 03 53 0C 30
					39 01 00 00 00 00 07 55 16 29 C0 04 78 DF
					15 01 00 00 00 00 02 B0 AC
					39 01 00 00 00 00 07 B8 3D 01 1F 01 FF 3C
					39 01 00 00 00 00 59 B9 11 00 00 89 30 80 0C 30 05 A0 00 3C 02 D0 02 D0 02 00 02 C2 00 20 05 D9 00 0A 00 0F 02 09 01 46 18 00 10 F0 03 0C 20 00 06 0B 0B 33 0E 1C 2A 38 46 54 62 69 70 77 79 7B 7D 7E 01 02 01 00 09 40 09 BE 19 FC 19 FA 19 F8 1A 38 1A 78 1A B6 2A B6 2A F4 2A F4 4B 34 63 74
					39 01 00 00 00 00 59 BA 11 00 00 89 30 80 09 24 04 38 00 3C 02 1C 02 1C 02 00 02 52 00 20 05 30 00 07 00 0F 02 09 01 B2 18 00 10 F0 03 0C 20 00 06 0B 0B 33 0E 1C 2A 38 46 54 62 69 70 77 79 7B 7D 7E 01 02 01 00 09 40 09 BE 19 FC 19 FA 19 F8 1A 38 1A 78 1A B6 2A B6 2A F4 2A F4 4B 34 63 74
					39 01 00 00 00 00 59 BB 11 00 00 89 30 80 06 18 02 D0 00 3C 01 68 01 68 02 00 01 E1 00 20 04 3A 00 05 00 0F 02 09 02 8B 18 00 10 F0 03 0C 20 00 06 0B 0B 33 0E 1C 2A 38 46 54 62 69 70 77 79 7B 7D 7E 01 02 01 00 09 40 09 BE 19 FC 19 FA 19 F8 1A 38 1A 78 1A B6 2A B6 2A F4 2A F4 4B 34 63 74
					39 01 00 00 00 00 0F CB 80 5C 07 11 34 54 4F 5A 33 19 60 00 00 00
					39 01 00 00 14 00 1F CD 00 00 00 1E 23 23 23 23 23 23 23 23 23 23 23 23 23 23 23 23 23 23 23 23 23 2C 2C 2C 28 28
					39 01 00 00 00 00 05 30 00 00 0C 2F
					15 01 00 00 00 00 02 B0 55
					39 01 00 00 00 00 21 CC 88 0A 4B 6C FF 58 60 60 80 67 70 80 7A 74 6E 60 79 65 60 60 68 74 67 87 7A 74 6A 60 7A 7A 5C 6C
					39 01 00 00 00 00 21 CD 6C 80 80 7A 79 75 6A 68 7C 83 83 83 83 83 83 83 83 83 83 83 83 83 83 83 83 83 83 83 83 83 83 83
					39 01 00 00 00 00 21 CE 83 83 83 83 83 83 83 7A 83 83 83 83 83 7F 7F 7F 7F 7F 7F 7F 7E 7E 7E 7F 7F F4 00 06 02 01 06 E4
					39 01 00 00 00 00 21 CF EF EF EF F6 06 00 0A 81 D3 FF 4C 50 48 48 4C 50 50 4A 45 4E 4C 52 54 54 54 58 58 68 65 6B 53 5B
					39 01 00 00 00 00 21 D0 50 56 6E 74 76 74 80 78 80 7C 72 6C 68 76 80 80 80 80 80 80 80 80 80 80 80 80 80 80 80 80 80 80
					39 01 00 00 00 00 21 D1 80 80 80 80 80 80 80 80 80 80 80 80 80 80 80 80 80 80 7F 7F 7F 7F 7F 7E 7F 7D 7E 7F 7F 7E FB FF
					39 01 00 00 00 00 21 D2 F6 F6 03 0C FA E9 EF FB 03 08 00 0A 81 D3 FF 48 44 44 4E 53 52 50 50 4C 60 54 50 4C 50 4C 56 5A
					39 01 00 00 00 00 21 D3 62 5F 60 5D 64 60 70 66 68 6C 74 70 79 77 70 80 80 80 80 80 80 80 80 80 80 80 80 80 80 80 80 80
					39 01 00 00 00 00 21 D4 80 80 80 80 80 80 80 80 80 80 80 80 80 80 80 80 80 80 80 80 80 80 80 7F 7F 7F 7E 7F 7F 7F 7E 7F
					39 01 00 00 00 00 21 D5 7D 7F 7F FB 04 06 0C 01 03 FC F2 06 15 FF F4 00 0A 81 D3 FF 48 46 40 3A 42 42 4C 4C 3C 38 38 44
					39 01 00 00 00 00 21 D6 4D 54 46 4A 49 58 59 5D 42 38 3A 4A 64 78 68 60 6F 58 70 66 5C 4A 4A 70 80 80 80 80 80 80 80 80
					39 01 00 00 00 00 21 D7 80 80 80 80 80 80 80 80 80 80 80 80 80 80 80 80 80 80 80 80 80 80 80 80 80 80 80 80 7F 7E 7D 7E
					39 01 00 00 00 00 15 D8 7F 7D 7F 7A 7C 7E 7F 7E FB F2 E9 F2 02 15 F8 DC E2 F2 03 0C
					39 01 00 00 00 00 21 EC 3F 03 01 56 AB FC 03 00 55 AA FC 03 00 55 AA FC 00 FF 40 80 C0 00 40 80 C0 00 40 80 C0 00 40 80
					39 01 00 00 00 00 21 ED C0 00 ED 3F 7E BD FB 3A 79 B8 F7 36 75 B4 F2 31 70 AF 00 D0 3D 7A B7 F4 31 6E AB E8 26 63 A0 DD
					39 01 00 00 00 00 04 EE 1A 57 94
					39 01 00 00 00 00 21 EF 00 03 FF 03 FF 00 80 01 00 01 80 02 00 02 80 03 00 03 80 03 FF 00 80 01 00 01 80 02 00 02 80 03
					39 01 00 00 00 00 21 F0 00 03 80 03 FF 00 80 01 00 01 80 02 00 02 80 03 00 03 80 03 FF 00 80 01 00 01 80 02 00 02 80 03
					39 01 00 00 14 00 06 F1 00 03 80 03 FF
					15 01 00 00 00 00 02 B0 AC
					39 01 00 00 00 00 43 E7 30 00 10 30 00 10 30 00 10 30 00 10 30 00 10 11 3A D7 11 88 89 11 D7 3A 02 25 EC 02 74 9D 02 C2 4F 30 00 10 30 00 10 30 00 10 30 00 10 30 00 10 11 3A D7 11 88 89 11 D7 3A 02 25 EC 02 74 9D 02 C2 4F
					39 01 00 00 00 00 1F E8 20 9D 74 11 3A D7 03 01 10 47 5E EA B1 0E 3A 20 9D 74 11 3A D7 03 01 10 47 5E EA B1 0E 3A
					39 01 00 00 00 00 19 D0 D2 21 23 1F 21 41 00 00 00 52 41 00 00 00 08 00 C4 11 11 9D 9D 06 00 00
					39 01 00 00 00 00 05 2A 00 00 05 9F
					39 01 00 00 14 00 05 2B 00 00 0C 2F
				];
				qcom,mdss-dsi-on-command-state = "dsi_lp_mode";

				qcom,mdss-dsi-post-panel-on-command = [
					05 01 00 00 14 00 01 29
				];

				qcom,mdss-dsi-off-command = [
					39 01 00 00 00 00 03 53 0C 30
					39 01 00 00 00 00 05 CA 08 90 18 05
					05 01 00 00 0A 00 01 28
					05 01 00 00 64 00 01 10
				];
				qcom,mdss-dsi-off-command-state = "dsi_lp_mode";

				iris,abyp-panel-command = [
					07 01 00 00 10 00 02 11 00
					39 01 00 00 11 00 05 2A 00 00 05 9F
					39 01 00 00 11 00 05 2B 00 00 0C 2F
				];
				iris,abyp-panel-command-state = "dsi_lp_mode";

				qcom,mdss-dsi-timing-switch-command = [
					15 00 00 00 00 00 02 B0 AC
					07 00 00 00 00 00 02 11 00
					15 01 00 00 00 00 02 3D 08
				];
				qcom,mdss-dsi-timing-switch-command-state = "dsi_lp_mode";

				qcom,mode-control-dsi-state = "dsi_lp_mode";
				qcom,mdss-dsi-pps-command-state = "dsi_hs_mode";

				qcom,compression-mode = "dsc";
				qcom,mdss-dsc-version = <0x11>;
				qcom,mdss-dsc-scr-version = <0x1>;
				qcom,mdss-dsc-slice-height = <60>;
				qcom,mdss-dsc-slice-width = <720>;
				qcom,mdss-dsc-slice-per-pkt = <2>;
				qcom,mdss-dsc-bit-per-component = <8>;
				qcom,mdss-dsc-bit-per-pixel = <8>;
				qcom,lm-split = <720 720>;
				qcom,mdss-dsc-encoders = <2>;
				qcom,mdss-dsc-block-prediction-enable;
			};
			timing@1 {
				qcom,partial-update-enabled = "single_roi";
				qcom,panel-roi-alignment = <1080 60 1080 60 1080 60>;
				qcom,mdss-dsi-panel-phy-timings = [00 1D 07 07 23 22 07 07 05 02 04 00 18 17];
				qcom,mdss-dsi-panel-clockrate = <920145600>;
				qcom,display-topology = <2 2 1>;
				qcom,default-topology-index = <0>;
				qcom,mdss-dsi-panel-framerate = <60>;
				qcom,mdss-dsi-panel-width = <1080>;
				qcom,mdss-dsi-panel-height = <2340>;
				qcom,mdss-dsi-h-front-porch = <188>;
				qcom,mdss-dsi-h-back-porch = <188>;
				qcom,mdss-dsi-h-pulse-width = <16>;
				qcom,mdss-dsi-h-sync-skew = <0>;
				qcom,mdss-dsi-v-back-porch = <450>;
				qcom,mdss-dsi-v-front-porch = <289>;
				qcom,mdss-dsi-v-pulse-width = <1>;
				qcom,mdss-dsi-h-left-border = <0>;
				qcom,mdss-dsi-h-right-border = <0>;
				qcom,mdss-dsi-v-top-border = <0>;
				qcom,mdss-dsi-v-bottom-border = <0>;
				qcom,mdss-dsi-h-sync-pulse = <0>;
				qcom,mdss-mdp-transfer-time-us = <15000>;

				qcom,mdss-dsi-on-command = [
					07 01 00 00 00 00 02 21 00
					15 01 00 00 00 00 02 B0 AC
					15 01 00 00 00 00 02 3D 09
					39 01 00 00 00 00 07 F8 01 49 0C FF 7F 04
					15 01 00 00 00 00 02 26 01
					15 01 00 00 00 00 02 35 00
					15 01 00 00 00 00 02 B0 CA
					05 01 00 00 3C 00 01 11
					39 01 00 00 00 00 03 51 00 01
					39 01 00 00 00 00 03 53 0C 30
					39 01 00 00 00 00 07 55 16 29 C0 04 78 DF
					15 01 00 00 00 00 02 B0 AC
					39 01 00 00 00 00 07 B8 3D 01 1F 01 FF 3C
					39 01 00 00 00 00 59 B9 11 00 00 89 30 80 0C 30 05 A0 00 3C 02 D0 02 D0 02 00 02 C2 00 20 05 D9 00 0A 00 0F 02 09 01 46 18 00 10 F0 03 0C 20 00 06 0B 0B 33 0E 1C 2A 38 46 54 62 69 70 77 79 7B 7D 7E 01 02 01 00 09 40 09 BE 19 FC 19 FA 19 F8 1A 38 1A 78 1A B6 2A B6 2A F4 2A F4 4B 34 63 74
					39 01 00 00 00 00 59 BA 11 00 00 89 30 80 09 24 04 38 00 3C 02 1C 02 1C 02 00 02 52 00 20 05 30 00 07 00 0F 02 09 01 B2 18 00 10 F0 03 0C 20 00 06 0B 0B 33 0E 1C 2A 38 46 54 62 69 70 77 79 7B 7D 7E 01 02 01 00 09 40 09 BE 19 FC 19 FA 19 F8 1A 38 1A 78 1A B6 2A B6 2A F4 2A F4 4B 34 63 74
					39 01 00 00 00 00 59 BB 11 00 00 89 30 80 06 18 02 D0 00 3C 01 68 01 68 02 00 01 E1 00 20 04 3A 00 05 00 0F 02 09 02 8B 18 00 10 F0 03 0C 20 00 06 0B 0B 33 0E 1C 2A 38 46 54 62 69 70 77 79 7B 7D 7E 01 02 01 00 09 40 09 BE 19 FC 19 FA 19 F8 1A 38 1A 78 1A B6 2A B6 2A F4 2A F4 4B 34 63 74
					39 01 00 00 00 00 0F CB 80 5C 07 11 34 54 4F 5A 33 19 60 00 00 00
					39 01 00 00 14 00 1F CD 00 00 00 1E 23 23 23 23 23 23 23 23 23 23 23 23 23 23 23 23 23 23 23 23 23 2C 2C 2C 28 28
					39 01 00 00 00 00 05 30 00 00 0C 2F
					15 01 00 00 00 00 02 B0 55
					39 01 00 00 00 00 21 CC 88 0A 4B 6C FF 58 60 60 80 67 70 80 7A 74 6E 60 79 65 60 60 68 74 67 87 7A 74 6A 60 7A 7A 5C 6C
					39 01 00 00 00 00 21 CD 6C 80 80 7A 79 75 6A 68 7C 83 83 83 83 83 83 83 83 83 83 83 83 83 83 83 83 83 83 83 83 83 83 83
					39 01 00 00 00 00 21 CE 83 83 83 83 83 83 83 7A 83 83 83 83 83 7F 7F 7F 7F 7F 7F 7F 7E 7E 7E 7F 7F F4 00 06 02 01 06 E4
					39 01 00 00 00 00 21 CF EF EF EF F6 06 00 0A 81 D3 FF 4C 50 48 48 4C 50 50 4A 45 4E 4C 52 54 54 54 58 58 68 65 6B 53 5B
					39 01 00 00 00 00 21 D0 50 56 6E 74 76 74 80 78 80 7C 72 6C 68 76 80 80 80 80 80 80 80 80 80 80 80 80 80 80 80 80 80 80
					39 01 00 00 00 00 21 D1 80 80 80 80 80 80 80 80 80 80 80 80 80 80 80 80 80 80 7F 7F 7F 7F 7F 7E 7F 7D 7E 7F 7F 7E FB FF
					39 01 00 00 00 00 21 D2 F6 F6 03 0C FA E9 EF FB 03 08 00 0A 81 D3 FF 48 44 44 4E 53 52 50 50 4C 60 54 50 4C 50 4C 56 5A
					39 01 00 00 00 00 21 D3 62 5F 60 5D 64 60 70 66 68 6C 74 70 79 77 70 80 80 80 80 80 80 80 80 80 80 80 80 80 80 80 80 80
					39 01 00 00 00 00 21 D4 80 80 80 80 80 80 80 80 80 80 80 80 80 80 80 80 80 80 80 80 80 80 80 7F 7F 7F 7E 7F 7F 7F 7E 7F
					39 01 00 00 00 00 21 D5 7D 7F 7F FB 04 06 0C 01 03 FC F2 06 15 FF F4 00 0A 81 D3 FF 48 46 40 3A 42 42 4C 4C 3C 38 38 44
					39 01 00 00 00 00 21 D6 4D 54 46 4A 49 58 59 5D 42 38 3A 4A 64 78 68 60 6F 58 70 66 5C 4A 4A 70 80 80 80 80 80 80 80 80
					39 01 00 00 00 00 21 D7 80 80 80 80 80 80 80 80 80 80 80 80 80 80 80 80 80 80 80 80 80 80 80 80 80 80 80 80 7F 7E 7D 7E
					39 01 00 00 00 00 15 D8 7F 7D 7F 7A 7C 7E 7F 7E FB F2 E9 F2 02 15 F8 DC E2 F2 03 0C
					39 01 00 00 00 00 21 EC 3F 03 01 56 AB FC 03 00 55 AA FC 03 00 55 AA FC 00 FF 40 80 C0 00 40 80 C0 00 40 80 C0 00 40 80
					39 01 00 00 00 00 21 ED C0 00 ED 3F 7E BD FB 3A 79 B8 F7 36 75 B4 F2 31 70 AF 00 D0 3D 7A B7 F4 31 6E AB E8 26 63 A0 DD
					39 01 00 00 00 00 04 EE 1A 57 94
					39 01 00 00 00 00 21 EF 00 03 FF 03 FF 00 80 01 00 01 80 02 00 02 80 03 00 03 80 03 FF 00 80 01 00 01 80 02 00 02 80 03
					39 01 00 00 00 00 21 F0 00 03 80 03 FF 00 80 01 00 01 80 02 00 02 80 03 00 03 80 03 FF 00 80 01 00 01 80 02 00 02 80 03
					39 01 00 00 14 00 06 F1 00 03 80 03 FF
					15 01 00 00 00 00 02 B0 AC
					39 01 00 00 00 00 43 E7 30 00 10 30 00 10 30 00 10 30 00 10 30 00 10 11 3A D7 11 88 89 11 D7 3A 02 25 EC 02 74 9D 02 C2 4F 30 00 10 30 00 10 30 00 10 30 00 10 30 00 10 11 3A D7 11 88 89 11 D7 3A 02 25 EC 02 74 9D 02 C2 4F
					39 01 00 00 00 00 1F E8 20 9D 74 11 3A D7 03 01 10 47 5E EA B1 0E 3A 20 9D 74 11 3A D7 03 01 10 47 5E EA B1 0E 3A
					39 01 00 00 00 00 19 D0 D2 21 23 1F 21 41 00 00 00 52 41 00 00 00 08 00 C4 11 11 9D 9D 06 00 00
					39 01 00 00 00 00 05 2A 00 00 05 9F
					39 01 00 00 14 00 05 2B 00 00 0C 2F
				];
				qcom,mdss-dsi-on-command-state = "dsi_lp_mode";

				qcom,mdss-dsi-post-panel-on-command = [
					05 01 00 00 14 00 01 29
				];

				qcom,mdss-dsi-off-command = [
					39 01 00 00 00 00 03 53 0C 30
					39 01 00 00 00 00 05 CA 08 90 18 05
					05 01 00 00 0A 00 01 28
					05 01 00 00 64 00 01 10
				];
				qcom,mdss-dsi-off-command-state = "dsi_lp_mode";

				iris,abyp-panel-command = [
					07 01 00 00 10 00 02 11 00
					39 01 00 00 11 00 05 2A 00 00 05 9F
					39 01 00 00 11 00 05 2B 00 00 0C 2F
				];
				iris,abyp-panel-command-state = "dsi_lp_mode";

				qcom,mdss-dsi-timing-switch-command = [
					15 00 00 00 00 00 02 B0 AC
					07 00 00 00 00 00 02 21 00
					15 01 00 00 00 00 02 3D 09
				];
				qcom,mdss-dsi-timing-switch-command-state = "dsi_lp_mode";

				qcom,mode-control-dsi-state = "dsi_lp_mode";
				qcom,mdss-dsi-pps-command-state = "dsi_hs_mode";

				qcom,compression-mode = "dsc";
				qcom,mdss-dsc-version = <0x11>;
				qcom,mdss-dsc-scr-version = <0x1>;
				qcom,mdss-dsc-slice-height = <60>;
				qcom,mdss-dsc-slice-width = <540>;
				qcom,mdss-dsc-slice-per-pkt = <2>;
				qcom,mdss-dsc-bit-per-component = <8>;
				qcom,mdss-dsc-bit-per-pixel = <8>;
				qcom,lm-split = <540 540>;
				qcom,mdss-dsc-encoders = <2>;
				qcom,mdss-dsc-block-prediction-enable;
			};

			timing@2{
				qcom,partial-update-enabled = "single_roi";
				qcom,panel-roi-alignment = <720 60 720 60 720 60>;
				qcom,mdss-dsi-panel-phy-timings = [00 1D 07 07 23 22 07 07 05 02 04 00 18 17];
				qcom,mdss-dsi-panel-clockrate = <920145600>;
				qcom,display-topology = <2 2 1>;
				qcom,default-topology-index = <0>;
				qcom,mdss-dsi-panel-framerate = <60>;
				qcom,mdss-dsi-panel-width = <720>;
				qcom,mdss-dsi-panel-height = <1560>;
				qcom,mdss-dsi-h-front-porch = <240>;
				qcom,mdss-dsi-h-back-porch = <240>;
				qcom,mdss-dsi-h-pulse-width = <48>;
				qcom,mdss-dsi-h-sync-skew = <0>;
				qcom,mdss-dsi-v-back-porch = <728>;
				qcom,mdss-dsi-v-front-porch = <728>;
				qcom,mdss-dsi-v-pulse-width = <4>;
				qcom,mdss-dsi-h-left-border = <0>;
				qcom,mdss-dsi-h-right-border = <0>;
				qcom,mdss-dsi-v-top-border = <0>;
				qcom,mdss-dsi-v-bottom-border = <0>;
				qcom,mdss-dsi-h-sync-pulse = <0>;
				qcom,mdss-mdp-transfer-time-us = <15000>;

				qcom,mdss-dsi-on-command = [
					07 01 00 00 00 00 02 31 00
					15 01 00 00 00 00 02 B0 AC
					15 01 00 00 00 00 02 3D 0B
					39 01 00 00 00 00 07 F8 01 49 0C FF 7F 04
					15 01 00 00 00 00 02 26 01
					15 01 00 00 00 00 02 35 00
					15 01 00 00 00 00 02 B0 CA
					05 01 00 00 3C 00 01 11
					39 01 00 00 00 00 03 51 00 01
					39 01 00 00 00 00 03 53 0C 30
					39 01 00 00 00 00 07 55 16 29 C0 04 78 DF
					15 01 00 00 00 00 02 B0 AC
					39 01 00 00 00 00 07 B8 3D 01 1F 01 FF 3C
					39 01 00 00 00 00 59 B9 11 00 00 89 30 80 0C 30 05 A0 00 3C 02 D0 02 D0 02 00 02 C2 00 20 05 D9 00 0A 00 0F 02 09 01 46 18 00 10 F0 03 0C 20 00 06 0B 0B 33 0E 1C 2A 38 46 54 62 69 70 77 79 7B 7D 7E 01 02 01 00 09 40 09 BE 19 FC 19 FA 19 F8 1A 38 1A 78 1A B6 2A B6 2A F4 2A F4 4B 34 63 74
					39 01 00 00 00 00 59 BA 11 00 00 89 30 80 09 24 04 38 00 3C 02 1C 02 1C 02 00 02 52 00 20 05 30 00 07 00 0F 02 09 01 B2 18 00 10 F0 03 0C 20 00 06 0B 0B 33 0E 1C 2A 38 46 54 62 69 70 77 79 7B 7D 7E 01 02 01 00 09 40 09 BE 19 FC 19 FA 19 F8 1A 38 1A 78 1A B6 2A B6 2A F4 2A F4 4B 34 63 74
					39 01 00 00 00 00 59 BB 11 00 00 89 30 80 06 18 02 D0 00 3C 01 68 01 68 02 00 01 E1 00 20 04 3A 00 05 00 0F 02 09 02 8B 18 00 10 F0 03 0C 20 00 06 0B 0B 33 0E 1C 2A 38 46 54 62 69 70 77 79 7B 7D 7E 01 02 01 00 09 40 09 BE 19 FC 19 FA 19 F8 1A 38 1A 78 1A B6 2A B6 2A F4 2A F4 4B 34 63 74
					39 01 00 00 00 00 0F CB 80 5C 07 11 34 54 4F 5A 33 19 60 00 00 00
					39 01 00 00 14 00 1F CD 00 00 00 1E 23 23 23 23 23 23 23 23 23 23 23 23 23 23 23 23 23 23 23 23 23 2C 2C 2C 28 28
					39 01 00 00 00 00 05 30 00 00 0C 2F
					15 01 00 00 00 00 02 B0 55
					39 01 00 00 00 00 21 CC 88 0A 4B 6C FF 58 60 60 80 67 70 80 7A 74 6E 60 79 65 60 60 68 74 67 87 7A 74 6A 60 7A 7A 5C 6C
					39 01 00 00 00 00 21 CD 6C 80 80 7A 79 75 6A 68 7C 83 83 83 83 83 83 83 83 83 83 83 83 83 83 83 83 83 83 83 83 83 83 83
					39 01 00 00 00 00 21 CE 83 83 83 83 83 83 83 7A 83 83 83 83 83 7F 7F 7F 7F 7F 7F 7F 7E 7E 7E 7F 7F F4 00 06 02 01 06 E4
					39 01 00 00 00 00 21 CF EF EF EF F6 06 00 0A 81 D3 FF 4C 50 48 48 4C 50 50 4A 45 4E 4C 52 54 54 54 58 58 68 65 6B 53 5B
					39 01 00 00 00 00 21 D0 50 56 6E 74 76 74 80 78 80 7C 72 6C 68 76 80 80 80 80 80 80 80 80 80 80 80 80 80 80 80 80 80 80
					39 01 00 00 00 00 21 D1 80 80 80 80 80 80 80 80 80 80 80 80 80 80 80 80 80 80 7F 7F 7F 7F 7F 7E 7F 7D 7E 7F 7F 7E FB FF
					39 01 00 00 00 00 21 D2 F6 F6 03 0C FA E9 EF FB 03 08 00 0A 81 D3 FF 48 44 44 4E 53 52 50 50 4C 60 54 50 4C 50 4C 56 5A
					39 01 00 00 00 00 21 D3 62 5F 60 5D 64 60 70 66 68 6C 74 70 79 77 70 80 80 80 80 80 80 80 80 80 80 80 80 80 80 80 80 80
					39 01 00 00 00 00 21 D4 80 80 80 80 80 80 80 80 80 80 80 80 80 80 80 80 80 80 80 80 80 80 80 7F 7F 7F 7E 7F 7F 7F 7E 7F
					39 01 00 00 00 00 21 D5 7D 7F 7F FB 04 06 0C 01 03 FC F2 06 15 FF F4 00 0A 81 D3 FF 48 46 40 3A 42 42 4C 4C 3C 38 38 44
					39 01 00 00 00 00 21 D6 4D 54 46 4A 49 58 59 5D 42 38 3A 4A 64 78 68 60 6F 58 70 66 5C 4A 4A 70 80 80 80 80 80 80 80 80
					39 01 00 00 00 00 21 D7 80 80 80 80 80 80 80 80 80 80 80 80 80 80 80 80 80 80 80 80 80 80 80 80 80 80 80 80 7F 7E 7D 7E
					39 01 00 00 00 00 15 D8 7F 7D 7F 7A 7C 7E 7F 7E FB F2 E9 F2 02 15 F8 DC E2 F2 03 0C
					39 01 00 00 00 00 21 EC 3F 03 01 56 AB FC 03 00 55 AA FC 03 00 55 AA FC 00 FF 40 80 C0 00 40 80 C0 00 40 80 C0 00 40 80
					39 01 00 00 00 00 21 ED C0 00 ED 3F 7E BD FB 3A 79 B8 F7 36 75 B4 F2 31 70 AF 00 D0 3D 7A B7 F4 31 6E AB E8 26 63 A0 DD
					39 01 00 00 00 00 04 EE 1A 57 94
					39 01 00 00 00 00 21 EF 00 03 FF 03 FF 00 80 01 00 01 80 02 00 02 80 03 00 03 80 03 FF 00 80 01 00 01 80 02 00 02 80 03
					39 01 00 00 00 00 21 F0 00 03 80 03 FF 00 80 01 00 01 80 02 00 02 80 03 00 03 80 03 FF 00 80 01 00 01 80 02 00 02 80 03
					39 01 00 00 14 00 06 F1 00 03 80 03 FF
					15 01 00 00 00 00 02 B0 AC
					39 01 00 00 00 00 43 E7 30 00 10 30 00 10 30 00 10 30 00 10 30 00 10 11 3A D7 11 88 89 11 D7 3A 02 25 EC 02 74 9D 02 C2 4F 30 00 10 30 00 10 30 00 10 30 00 10 30 00 10 11 3A D7 11 88 89 11 D7 3A 02 25 EC 02 74 9D 02 C2 4F
					39 01 00 00 00 00 1F E8 20 9D 74 11 3A D7 03 01 10 47 5E EA B1 0E 3A 20 9D 74 11 3A D7 03 01 10 47 5E EA B1 0E 3A
					39 01 00 00 00 00 19 D0 D2 21 23 1F 21 41 00 00 00 52 41 00 00 00 08 00 C4 11 11 9D 9D 06 00 00
					39 01 00 00 00 00 05 2A 00 00 05 9F
					39 01 00 00 14 00 05 2B 00 00 0C 2F
				];
				qcom,mdss-dsi-on-command-state = "dsi_lp_mode";

				qcom,mdss-dsi-post-panel-on-command = [
					05 01 00 00 14 00 01 29
				];

				qcom,mdss-dsi-off-command = [
					39 01 00 00 00 00 03 53 0C 30
					39 01 00 00 00 00 05 CA 08 90 18 05
					05 01 00 00 0A 00 01 28
					05 01 00 00 64 00 01 10
				];
				qcom,mdss-dsi-off-command-state = "dsi_lp_mode";

				iris,abyp-panel-command = [
					07 01 00 00 10 00 02 11 00
					39 01 00 00 11 00 05 2A 00 00 05 9F
					39 01 00 00 11 00 05 2B 00 00 0C 2F
				];
				iris,abyp-panel-command-state = "dsi_lp_mode";

				qcom,mdss-dsi-timing-switch-command = [
					15 00 00 00 00 00 02 B0 AC
					07 00 00 00 00 00 02 31 00
					15 01 00 00 00 00 02 3D 0B
				];
				qcom,mdss-dsi-timing-switch-command-state = "dsi_lp_mode";

				qcom,mode-control-dsi-state = "dsi_lp_mode";
				qcom,mdss-dsi-pps-command-state = "dsi_hs_mode";

				qcom,compression-mode = "dsc";
				qcom,mdss-dsc-version = <0x11>;
				qcom,mdss-dsc-scr-version = <0x1>;
				qcom,mdss-dsc-slice-height = <60>;
				qcom,mdss-dsc-slice-width = <360>;
				qcom,mdss-dsc-slice-per-pkt = <2>;
				qcom,mdss-dsc-bit-per-component = <8>;
				qcom,mdss-dsc-bit-per-pixel = <8>;
				qcom,lm-split = <360 360>;
				qcom,mdss-dsc-encoders = <2>;
				qcom,mdss-dsc-block-prediction-enable;
			};

			timing_30Hz@3{
				qcom,partial-update-enabled = "single_roi";
				qcom,panel-roi-alignment = <1440 60 1440 60 1440 60>;
				qcom,mdss-dsi-panel-phy-timings = [00 1D 07 07 23 22 07 07 05 02 04 00 18 17];
				qcom,mdss-dsi-panel-clockrate = <920145600>;
				qcom,display-topology = <2 2 1>;
				qcom,default-topology-index = <0>;
				qcom,mdss-dsi-panel-framerate = <60>;
				qcom,mdss-dsi-panel-width = <1440>;
				qcom,mdss-dsi-panel-height = <3120>;
				qcom,mdss-dsi-h-front-porch = <168>;
				qcom,mdss-dsi-h-back-porch = <88>;
				qcom,mdss-dsi-h-pulse-width = <4>;
				qcom,mdss-dsi-h-sync-skew = <0>;
				qcom,mdss-dsi-v-back-porch = <10>;
				qcom,mdss-dsi-v-front-porch = <9>;
				qcom,mdss-dsi-v-pulse-width = <1>;
				qcom,mdss-dsi-h-left-border = <0>;
				qcom,mdss-dsi-h-right-border = <0>;
				qcom,mdss-dsi-v-top-border = <0>;
				qcom,mdss-dsi-v-bottom-border = <0>;
				qcom,mdss-dsi-h-sync-pulse = <0>;
				qcom,mdss-mdp-transfer-time-us = <15000>;
				lge,mdss-dsi-panel-framerate-div = <2>;

				qcom,mdss-dsi-on-command = [
					07 01 00 00 00 00 02 11 00
					15 01 00 00 00 00 02 B0 AC
					15 01 00 00 00 00 02 3D 08
					39 01 00 00 00 00 07 F8 01 49 0C FF 7F 04
					15 01 00 00 00 00 02 26 01
					15 01 00 00 00 00 02 35 00
					15 01 00 00 00 00 02 B0 CA
					05 01 00 00 3C 00 01 11
					39 01 00 00 00 00 03 51 00 01
					39 01 00 00 00 00 03 53 0C 30
					39 01 00 00 00 00 07 55 16 29 C0 04 78 DF
					15 01 00 00 00 00 02 B0 AC
					39 01 00 00 00 00 07 B8 3D 01 1F 01 FF 3C
					39 01 00 00 00 00 59 B9 11 00 00 89 30 80 0C 30 05 A0 00 3C 02 D0 02 D0 02 00 02 C2 00 20 05 D9 00 0A 00 0F 02 09 01 46 18 00 10 F0 03 0C 20 00 06 0B 0B 33 0E 1C 2A 38 46 54 62 69 70 77 79 7B 7D 7E 01 02 01 00 09 40 09 BE 19 FC 19 FA 19 F8 1A 38 1A 78 1A B6 2A B6 2A F4 2A F4 4B 34 63 74
					39 01 00 00 00 00 59 BA 11 00 00 89 30 80 09 24 04 38 00 3C 02 1C 02 1C 02 00 02 52 00 20 05 30 00 07 00 0F 02 09 01 B2 18 00 10 F0 03 0C 20 00 06 0B 0B 33 0E 1C 2A 38 46 54 62 69 70 77 79 7B 7D 7E 01 02 01 00 09 40 09 BE 19 FC 19 FA 19 F8 1A 38 1A 78 1A B6 2A B6 2A F4 2A F4 4B 34 63 74
					39 01 00 00 00 00 59 BB 11 00 00 89 30 80 06 18 02 D0 00 3C 01 68 01 68 02 00 01 E1 00 20 04 3A 00 05 00 0F 02 09 02 8B 18 00 10 F0 03 0C 20 00 06 0B 0B 33 0E 1C 2A 38 46 54 62 69 70 77 79 7B 7D 7E 01 02 01 00 09 40 09 BE 19 FC 19 FA 19 F8 1A 38 1A 78 1A B6 2A B6 2A F4 2A F4 4B 34 63 74
					39 01 00 00 00 00 0F CB 80 5C 07 11 34 54 4F 5A 33 19 60 00 00 00
					39 01 00 00 14 00 1F CD 00 00 00 1E 23 23 23 23 23 23 23 23 23 23 23 23 23 23 23 23 23 23 23 23 23 2C 2C 2C 28 28
					39 01 00 00 00 00 05 30 00 00 0C 2F
					15 01 00 00 00 00 02 B0 55
					39 01 00 00 00 00 21 CC 88 0A 4B 6C FF 58 60 60 80 67 70 80 7A 74 6E 60 79 65 60 60 68 74 67 87 7A 74 6A 60 7A 7A 5C 6C
					39 01 00 00 00 00 21 CD 6C 80 80 7A 79 75 6A 68 7C 83 83 83 83 83 83 83 83 83 83 83 83 83 83 83 83 83 83 83 83 83 83 83
					39 01 00 00 00 00 21 CE 83 83 83 83 83 83 83 7A 83 83 83 83 83 7F 7F 7F 7F 7F 7F 7F 7E 7E 7E 7F 7F F4 00 06 02 01 06 E4
					39 01 00 00 00 00 21 CF EF EF EF F6 06 00 0A 81 D3 FF 4C 50 48 48 4C 50 50 4A 45 4E 4C 52 54 54 54 58 58 68 65 6B 53 5B
					39 01 00 00 00 00 21 D0 50 56 6E 74 76 74 80 78 80 7C 72 6C 68 76 80 80 80 80 80 80 80 80 80 80 80 80 80 80 80 80 80 80
					39 01 00 00 00 00 21 D1 80 80 80 80 80 80 80 80 80 80 80 80 80 80 80 80 80 80 7F 7F 7F 7F 7F 7E 7F 7D 7E 7F 7F 7E FB FF
					39 01 00 00 00 00 21 D2 F6 F6 03 0C FA E9 EF FB 03 08 00 0A 81 D3 FF 48 44 44 4E 53 52 50 50 4C 60 54 50 4C 50 4C 56 5A
					39 01 00 00 00 00 21 D3 62 5F 60 5D 64 60 70 66 68 6C 74 70 79 77 70 80 80 80 80 80 80 80 80 80 80 80 80 80 80 80 80 80
					39 01 00 00 00 00 21 D4 80 80 80 80 80 80 80 80 80 80 80 80 80 80 80 80 80 80 80 80 80 80 80 7F 7F 7F 7E 7F 7F 7F 7E 7F
					39 01 00 00 00 00 21 D5 7D 7F 7F FB 04 06 0C 01 03 FC F2 06 15 FF F4 00 0A 81 D3 FF 48 46 40 3A 42 42 4C 4C 3C 38 38 44
					39 01 00 00 00 00 21 D6 4D 54 46 4A 49 58 59 5D 42 38 3A 4A 64 78 68 60 6F 58 70 66 5C 4A 4A 70 80 80 80 80 80 80 80 80
					39 01 00 00 00 00 21 D7 80 80 80 80 80 80 80 80 80 80 80 80 80 80 80 80 80 80 80 80 80 80 80 80 80 80 80 80 7F 7E 7D 7E
					39 01 00 00 00 00 15 D8 7F 7D 7F 7A 7C 7E 7F 7E FB F2 E9 F2 02 15 F8 DC E2 F2 03 0C
					39 01 00 00 00 00 21 EC 3F 03 01 56 AB FC 03 00 55 AA FC 03 00 55 AA FC 00 FF 40 80 C0 00 40 80 C0 00 40 80 C0 00 40 80
					39 01 00 00 00 00 21 ED C0 00 ED 3F 7E BD FB 3A 79 B8 F7 36 75 B4 F2 31 70 AF 00 D0 3D 7A B7 F4 31 6E AB E8 26 63 A0 DD
					39 01 00 00 00 00 04 EE 1A 57 94
					39 01 00 00 00 00 21 EF 00 03 FF 03 FF 00 80 01 00 01 80 02 00 02 80 03 00 03 80 03 FF 00 80 01 00 01 80 02 00 02 80 03
					39 01 00 00 00 00 21 F0 00 03 80 03 FF 00 80 01 00 01 80 02 00 02 80 03 00 03 80 03 FF 00 80 01 00 01 80 02 00 02 80 03
					39 01 00 00 14 00 06 F1 00 03 80 03 FF
					15 01 00 00 00 00 02 B0 AC
					39 01 00 00 00 00 43 E7 30 00 10 30 00 10 30 00 10 30 00 10 30 00 10 11 3A D7 11 88 89 11 D7 3A 02 25 EC 02 74 9D 02 C2 4F 30 00 10 30 00 10 30 00 10 30 00 10 30 00 10 11 3A D7 11 88 89 11 D7 3A 02 25 EC 02 74 9D 02 C2 4F
					39 01 00 00 00 00 1F E8 20 9D 74 11 3A D7 03 01 10 47 5E EA B1 0E 3A 20 9D 74 11 3A D7 03 01 10 47 5E EA B1 0E 3A
					39 01 00 00 00 00 19 D0 D2 21 23 1F 21 41 00 00 00 52 41 00 00 00 08 00 C4 11 11 9D 9D 06 00 00
					39 01 00 00 00 00 05 2A 00 00 05 9F
					39 01 00 00 14 00 05 2B 00 00 0C 2F
				];
				qcom,mdss-dsi-on-command-state = "dsi_lp_mode";

				qcom,mdss-dsi-post-panel-on-command = [
					05 01 00 00 14 00 01 29
				];

				qcom,mdss-dsi-off-command = [
					39 01 00 00 00 00 03 53 0C 30
					39 01 00 00 00 00 05 CA 08 90 18 05
					05 01 00 00 0A 00 01 28
					05 01 00 00 64 00 01 10
				];
				qcom,mdss-dsi-off-command-state = "dsi_lp_mode";

				iris,abyp-panel-command = [
					07 01 00 00 10 00 02 11 00
					39 01 00 00 11 00 05 2A 00 00 05 9F
					39 01 00 00 11 00 05 2B 00 00 0C 2F
				];
				iris,abyp-panel-command-state = "dsi_lp_mode";

				qcom,mdss-dsi-timing-switch-command = [
					15 00 00 00 00 00 02 B0 AC
					07 00 00 00 00 00 02 11 00
					15 01 00 00 00 00 02 3D 08
				];
				qcom,mdss-dsi-timing-switch-command-state = "dsi_lp_mode";

				qcom,mode-control-dsi-state = "dsi_lp_mode";
				qcom,mdss-dsi-pps-command-state = "dsi_hs_mode";

				qcom,compression-mode = "dsc";
				qcom,mdss-dsc-version = <0x11>;
				qcom,mdss-dsc-scr-version = <0x1>;
				qcom,mdss-dsc-slice-height = <60>;
				qcom,mdss-dsc-slice-width = <720>;
				qcom,mdss-dsc-slice-per-pkt = <2>;
				qcom,mdss-dsc-bit-per-component = <8>;
				qcom,mdss-dsc-bit-per-pixel = <8>;
				qcom,lm-split = <720 720>;
				qcom,mdss-dsc-encoders = <2>;
				qcom,mdss-dsc-block-prediction-enable;
			};
			timing_30Hz@4 {
				qcom,partial-update-enabled = "single_roi";
				qcom,panel-roi-alignment = <1080 60 1080 60 1080 60>;
				qcom,mdss-dsi-panel-phy-timings = [00 1D 07 07 23 22 07 07 05 02 04 00 18 17];
				qcom,mdss-dsi-panel-clockrate = <920145600>;
				qcom,display-topology = <2 2 1>;
				qcom,default-topology-index = <0>;
				qcom,mdss-dsi-panel-framerate = <60>;
				qcom,mdss-dsi-panel-width = <1080>;
				qcom,mdss-dsi-panel-height = <2340>;
				qcom,mdss-dsi-h-front-porch = <188>;
				qcom,mdss-dsi-h-back-porch = <188>;
				qcom,mdss-dsi-h-pulse-width = <16>;
				qcom,mdss-dsi-h-sync-skew = <0>;
				qcom,mdss-dsi-v-back-porch = <450>;
				qcom,mdss-dsi-v-front-porch = <289>;
				qcom,mdss-dsi-v-pulse-width = <1>;
				qcom,mdss-dsi-h-left-border = <0>;
				qcom,mdss-dsi-h-right-border = <0>;
				qcom,mdss-dsi-v-top-border = <0>;
				qcom,mdss-dsi-v-bottom-border = <0>;
				qcom,mdss-dsi-h-sync-pulse = <0>;
				qcom,mdss-mdp-transfer-time-us = <15000>;
				lge,mdss-dsi-panel-framerate-div = <2>;

				qcom,mdss-dsi-on-command = [
					07 01 00 00 00 00 02 21 00
					15 01 00 00 00 00 02 B0 AC
					15 01 00 00 00 00 02 3D 09
					39 01 00 00 00 00 07 F8 01 49 0C FF 7F 04
					15 01 00 00 00 00 02 26 01
					15 01 00 00 00 00 02 35 00
					15 01 00 00 00 00 02 B0 CA
					05 01 00 00 3C 00 01 11
					39 01 00 00 00 00 03 51 00 01
					39 01 00 00 00 00 03 53 0C 30
					39 01 00 00 00 00 07 55 16 29 C0 04 78 DF
					15 01 00 00 00 00 02 B0 AC
					39 01 00 00 00 00 07 B8 3D 01 1F 01 FF 3C
					39 01 00 00 00 00 59 B9 11 00 00 89 30 80 0C 30 05 A0 00 3C 02 D0 02 D0 02 00 02 C2 00 20 05 D9 00 0A 00 0F 02 09 01 46 18 00 10 F0 03 0C 20 00 06 0B 0B 33 0E 1C 2A 38 46 54 62 69 70 77 79 7B 7D 7E 01 02 01 00 09 40 09 BE 19 FC 19 FA 19 F8 1A 38 1A 78 1A B6 2A B6 2A F4 2A F4 4B 34 63 74
					39 01 00 00 00 00 59 BA 11 00 00 89 30 80 09 24 04 38 00 3C 02 1C 02 1C 02 00 02 52 00 20 05 30 00 07 00 0F 02 09 01 B2 18 00 10 F0 03 0C 20 00 06 0B 0B 33 0E 1C 2A 38 46 54 62 69 70 77 79 7B 7D 7E 01 02 01 00 09 40 09 BE 19 FC 19 FA 19 F8 1A 38 1A 78 1A B6 2A B6 2A F4 2A F4 4B 34 63 74
					39 01 00 00 00 00 59 BB 11 00 00 89 30 80 06 18 02 D0 00 3C 01 68 01 68 02 00 01 E1 00 20 04 3A 00 05 00 0F 02 09 02 8B 18 00 10 F0 03 0C 20 00 06 0B 0B 33 0E 1C 2A 38 46 54 62 69 70 77 79 7B 7D 7E 01 02 01 00 09 40 09 BE 19 FC 19 FA 19 F8 1A 38 1A 78 1A B6 2A B6 2A F4 2A F4 4B 34 63 74
					39 01 00 00 00 00 0F CB 80 5C 07 11 34 54 4F 5A 33 19 60 00 00 00
					39 01 00 00 14 00 1F CD 00 00 00 1E 23 23 23 23 23 23 23 23 23 23 23 23 23 23 23 23 23 23 23 23 23 2C 2C 2C 28 28
					39 01 00 00 00 00 05 30 00 00 0C 2F
					15 01 00 00 00 00 02 B0 55
					39 01 00 00 00 00 21 CC 88 0A 4B 6C FF 58 60 60 80 67 70 80 7A 74 6E 60 79 65 60 60 68 74 67 87 7A 74 6A 60 7A 7A 5C 6C
					39 01 00 00 00 00 21 CD 6C 80 80 7A 79 75 6A 68 7C 83 83 83 83 83 83 83 83 83 83 83 83 83 83 83 83 83 83 83 83 83 83 83
					39 01 00 00 00 00 21 CE 83 83 83 83 83 83 83 7A 83 83 83 83 83 7F 7F 7F 7F 7F 7F 7F 7E 7E 7E 7F 7F F4 00 06 02 01 06 E4
					39 01 00 00 00 00 21 CF EF EF EF F6 06 00 0A 81 D3 FF 4C 50 48 48 4C 50 50 4A 45 4E 4C 52 54 54 54 58 58 68 65 6B 53 5B
					39 01 00 00 00 00 21 D0 50 56 6E 74 76 74 80 78 80 7C 72 6C 68 76 80 80 80 80 80 80 80 80 80 80 80 80 80 80 80 80 80 80
					39 01 00 00 00 00 21 D1 80 80 80 80 80 80 80 80 80 80 80 80 80 80 80 80 80 80 7F 7F 7F 7F 7F 7E 7F 7D 7E 7F 7F 7E FB FF
					39 01 00 00 00 00 21 D2 F6 F6 03 0C FA E9 EF FB 03 08 00 0A 81 D3 FF 48 44 44 4E 53 52 50 50 4C 60 54 50 4C 50 4C 56 5A
					39 01 00 00 00 00 21 D3 62 5F 60 5D 64 60 70 66 68 6C 74 70 79 77 70 80 80 80 80 80 80 80 80 80 80 80 80 80 80 80 80 80
					39 01 00 00 00 00 21 D4 80 80 80 80 80 80 80 80 80 80 80 80 80 80 80 80 80 80 80 80 80 80 80 7F 7F 7F 7E 7F 7F 7F 7E 7F
					39 01 00 00 00 00 21 D5 7D 7F 7F FB 04 06 0C 01 03 FC F2 06 15 FF F4 00 0A 81 D3 FF 48 46 40 3A 42 42 4C 4C 3C 38 38 44
					39 01 00 00 00 00 21 D6 4D 54 46 4A 49 58 59 5D 42 38 3A 4A 64 78 68 60 6F 58 70 66 5C 4A 4A 70 80 80 80 80 80 80 80 80
					39 01 00 00 00 00 21 D7 80 80 80 80 80 80 80 80 80 80 80 80 80 80 80 80 80 80 80 80 80 80 80 80 80 80 80 80 7F 7E 7D 7E
					39 01 00 00 00 00 15 D8 7F 7D 7F 7A 7C 7E 7F 7E FB F2 E9 F2 02 15 F8 DC E2 F2 03 0C
					39 01 00 00 00 00 21 EC 3F 03 01 56 AB FC 03 00 55 AA FC 03 00 55 AA FC 00 FF 40 80 C0 00 40 80 C0 00 40 80 C0 00 40 80
					39 01 00 00 00 00 21 ED C0 00 ED 3F 7E BD FB 3A 79 B8 F7 36 75 B4 F2 31 70 AF 00 D0 3D 7A B7 F4 31 6E AB E8 26 63 A0 DD
					39 01 00 00 00 00 04 EE 1A 57 94
					39 01 00 00 00 00 21 EF 00 03 FF 03 FF 00 80 01 00 01 80 02 00 02 80 03 00 03 80 03 FF 00 80 01 00 01 80 02 00 02 80 03
					39 01 00 00 00 00 21 F0 00 03 80 03 FF 00 80 01 00 01 80 02 00 02 80 03 00 03 80 03 FF 00 80 01 00 01 80 02 00 02 80 03
					39 01 00 00 14 00 06 F1 00 03 80 03 FF
					15 01 00 00 00 00 02 B0 AC
					39 01 00 00 00 00 43 E7 30 00 10 30 00 10 30 00 10 30 00 10 30 00 10 11 3A D7 11 88 89 11 D7 3A 02 25 EC 02 74 9D 02 C2 4F 30 00 10 30 00 10 30 00 10 30 00 10 30 00 10 11 3A D7 11 88 89 11 D7 3A 02 25 EC 02 74 9D 02 C2 4F
					39 01 00 00 00 00 1F E8 20 9D 74 11 3A D7 03 01 10 47 5E EA B1 0E 3A 20 9D 74 11 3A D7 03 01 10 47 5E EA B1 0E 3A
					39 01 00 00 00 00 19 D0 D2 21 23 1F 21 41 00 00 00 52 41 00 00 00 08 00 C4 11 11 9D 9D 06 00 00
					39 01 00 00 00 00 05 2A 00 00 05 9F
					39 01 00 00 14 00 05 2B 00 00 0C 2F
				];
				qcom,mdss-dsi-on-command-state = "dsi_lp_mode";

				qcom,mdss-dsi-post-panel-on-command = [
					05 01 00 00 14 00 01 29
				];

				qcom,mdss-dsi-off-command = [
					39 01 00 00 00 00 03 53 0C 30
					39 01 00 00 00 00 05 CA 08 90 18 05
					05 01 00 00 0A 00 01 28
					05 01 00 00 64 00 01 10
				];
				qcom,mdss-dsi-off-command-state = "dsi_lp_mode";

				iris,abyp-panel-command = [
					07 01 00 00 10 00 02 11 00
					39 01 00 00 11 00 05 2A 00 00 05 9F
					39 01 00 00 11 00 05 2B 00 00 0C 2F
				];
				iris,abyp-panel-command-state = "dsi_lp_mode";

				qcom,mdss-dsi-timing-switch-command = [
					15 00 00 00 00 00 02 B0 AC
					07 00 00 00 00 00 02 21 00
					15 01 00 00 00 00 02 3D 09
				];
				qcom,mdss-dsi-timing-switch-command-state = "dsi_lp_mode";

				qcom,mode-control-dsi-state = "dsi_lp_mode";
				qcom,mdss-dsi-pps-command-state = "dsi_hs_mode";

				qcom,compression-mode = "dsc";
				qcom,mdss-dsc-version = <0x11>;
				qcom,mdss-dsc-scr-version = <0x1>;
				qcom,mdss-dsc-slice-height = <60>;
				qcom,mdss-dsc-slice-width = <540>;
				qcom,mdss-dsc-slice-per-pkt = <2>;
				qcom,mdss-dsc-bit-per-component = <8>;
				qcom,mdss-dsc-bit-per-pixel = <8>;
				qcom,lm-split = <540 540>;
				qcom,mdss-dsc-encoders = <2>;
				qcom,mdss-dsc-block-prediction-enable;
			};

			timing_30Hz@5{
				qcom,partial-update-enabled = "single_roi";
				qcom,panel-roi-alignment = <720 60 720 60 720 60>;
				qcom,mdss-dsi-panel-phy-timings = [00 1D 07 07 23 22 07 07 05 02 04 00 18 17];
				qcom,mdss-dsi-panel-clockrate = <920145600>;
				qcom,display-topology = <2 2 1>;
				qcom,default-topology-index = <0>;
				qcom,mdss-dsi-panel-framerate = <60>;
				qcom,mdss-dsi-panel-width = <720>;
				qcom,mdss-dsi-panel-height = <1560>;
				qcom,mdss-dsi-h-front-porch = <240>;
				qcom,mdss-dsi-h-back-porch = <240>;
				qcom,mdss-dsi-h-pulse-width = <48>;
				qcom,mdss-dsi-h-sync-skew = <0>;
				qcom,mdss-dsi-v-back-porch = <728>;
				qcom,mdss-dsi-v-front-porch = <728>;
				qcom,mdss-dsi-v-pulse-width = <4>;
				qcom,mdss-dsi-h-left-border = <0>;
				qcom,mdss-dsi-h-right-border = <0>;
				qcom,mdss-dsi-v-top-border = <0>;
				qcom,mdss-dsi-v-bottom-border = <0>;
				qcom,mdss-dsi-h-sync-pulse = <0>;
				qcom,mdss-mdp-transfer-time-us = <15000>;
				lge,mdss-dsi-panel-framerate-div = <2>;

				qcom,mdss-dsi-on-command = [
					07 01 00 00 00 00 02 31 00
					15 01 00 00 00 00 02 B0 AC
					15 01 00 00 00 00 02 3D 0B
					39 01 00 00 00 00 07 F8 01 49 0C FF 7F 04
					15 01 00 00 00 00 02 26 01
					15 01 00 00 00 00 02 35 00
					15 01 00 00 00 00 02 B0 CA
					05 01 00 00 3C 00 01 11
					39 01 00 00 00 00 03 51 00 01
					39 01 00 00 00 00 03 53 0C 30
					39 01 00 00 00 00 07 55 16 29 C0 04 78 DF
					15 01 00 00 00 00 02 B0 AC
					39 01 00 00 00 00 07 B8 3D 01 1F 01 FF 3C
					39 01 00 00 00 00 59 B9 11 00 00 89 30 80 0C 30 05 A0 00 3C 02 D0 02 D0 02 00 02 C2 00 20 05 D9 00 0A 00 0F 02 09 01 46 18 00 10 F0 03 0C 20 00 06 0B 0B 33 0E 1C 2A 38 46 54 62 69 70 77 79 7B 7D 7E 01 02 01 00 09 40 09 BE 19 FC 19 FA 19 F8 1A 38 1A 78 1A B6 2A B6 2A F4 2A F4 4B 34 63 74
					39 01 00 00 00 00 59 BA 11 00 00 89 30 80 09 24 04 38 00 3C 02 1C 02 1C 02 00 02 52 00 20 05 30 00 07 00 0F 02 09 01 B2 18 00 10 F0 03 0C 20 00 06 0B 0B 33 0E 1C 2A 38 46 54 62 69 70 77 79 7B 7D 7E 01 02 01 00 09 40 09 BE 19 FC 19 FA 19 F8 1A 38 1A 78 1A B6 2A B6 2A F4 2A F4 4B 34 63 74
					39 01 00 00 00 00 59 BB 11 00 00 89 30 80 06 18 02 D0 00 3C 01 68 01 68 02 00 01 E1 00 20 04 3A 00 05 00 0F 02 09 02 8B 18 00 10 F0 03 0C 20 00 06 0B 0B 33 0E 1C 2A 38 46 54 62 69 70 77 79 7B 7D 7E 01 02 01 00 09 40 09 BE 19 FC 19 FA 19 F8 1A 38 1A 78 1A B6 2A B6 2A F4 2A F4 4B 34 63 74
					39 01 00 00 00 00 0F CB 80 5C 07 11 34 54 4F 5A 33 19 60 00 00 00
					39 01 00 00 14 00 1F CD 00 00 00 1E 23 23 23 23 23 23 23 23 23 23 23 23 23 23 23 23 23 23 23 23 23 2C 2C 2C 28 28
					39 01 00 00 00 00 05 30 00 00 0C 2F
					15 01 00 00 00 00 02 B0 55
					39 01 00 00 00 00 21 CC 88 0A 4B 6C FF 58 60 60 80 67 70 80 7A 74 6E 60 79 65 60 60 68 74 67 87 7A 74 6A 60 7A 7A 5C 6C
					39 01 00 00 00 00 21 CD 6C 80 80 7A 79 75 6A 68 7C 83 83 83 83 83 83 83 83 83 83 83 83 83 83 83 83 83 83 83 83 83 83 83
					39 01 00 00 00 00 21 CE 83 83 83 83 83 83 83 7A 83 83 83 83 83 7F 7F 7F 7F 7F 7F 7F 7E 7E 7E 7F 7F F4 00 06 02 01 06 E4
					39 01 00 00 00 00 21 CF EF EF EF F6 06 00 0A 81 D3 FF 4C 50 48 48 4C 50 50 4A 45 4E 4C 52 54 54 54 58 58 68 65 6B 53 5B
					39 01 00 00 00 00 21 D0 50 56 6E 74 76 74 80 78 80 7C 72 6C 68 76 80 80 80 80 80 80 80 80 80 80 80 80 80 80 80 80 80 80
					39 01 00 00 00 00 21 D1 80 80 80 80 80 80 80 80 80 80 80 80 80 80 80 80 80 80 7F 7F 7F 7F 7F 7E 7F 7D 7E 7F 7F 7E FB FF
					39 01 00 00 00 00 21 D2 F6 F6 03 0C FA E9 EF FB 03 08 00 0A 81 D3 FF 48 44 44 4E 53 52 50 50 4C 60 54 50 4C 50 4C 56 5A
					39 01 00 00 00 00 21 D3 62 5F 60 5D 64 60 70 66 68 6C 74 70 79 77 70 80 80 80 80 80 80 80 80 80 80 80 80 80 80 80 80 80
					39 01 00 00 00 00 21 D4 80 80 80 80 80 80 80 80 80 80 80 80 80 80 80 80 80 80 80 80 80 80 80 7F 7F 7F 7E 7F 7F 7F 7E 7F
					39 01 00 00 00 00 21 D5 7D 7F 7F FB 04 06 0C 01 03 FC F2 06 15 FF F4 00 0A 81 D3 FF 48 46 40 3A 42 42 4C 4C 3C 38 38 44
					39 01 00 00 00 00 21 D6 4D 54 46 4A 49 58 59 5D 42 38 3A 4A 64 78 68 60 6F 58 70 66 5C 4A 4A 70 80 80 80 80 80 80 80 80
					39 01 00 00 00 00 21 D7 80 80 80 80 80 80 80 80 80 80 80 80 80 80 80 80 80 80 80 80 80 80 80 80 80 80 80 80 7F 7E 7D 7E
					39 01 00 00 00 00 15 D8 7F 7D 7F 7A 7C 7E 7F 7E FB F2 E9 F2 02 15 F8 DC E2 F2 03 0C
					39 01 00 00 00 00 21 EC 3F 03 01 56 AB FC 03 00 55 AA FC 03 00 55 AA FC 00 FF 40 80 C0 00 40 80 C0 00 40 80 C0 00 40 80
					39 01 00 00 00 00 21 ED C0 00 ED 3F 7E BD FB 3A 79 B8 F7 36 75 B4 F2 31 70 AF 00 D0 3D 7A B7 F4 31 6E AB E8 26 63 A0 DD
					39 01 00 00 00 00 04 EE 1A 57 94
					39 01 00 00 00 00 21 EF 00 03 FF 03 FF 00 80 01 00 01 80 02 00 02 80 03 00 03 80 03 FF 00 80 01 00 01 80 02 00 02 80 03
					39 01 00 00 00 00 21 F0 00 03 80 03 FF 00 80 01 00 01 80 02 00 02 80 03 00 03 80 03 FF 00 80 01 00 01 80 02 00 02 80 03
					39 01 00 00 14 00 06 F1 00 03 80 03 FF
					15 01 00 00 00 00 02 B0 AC
					39 01 00 00 00 00 43 E7 30 00 10 30 00 10 30 00 10 30 00 10 30 00 10 11 3A D7 11 88 89 11 D7 3A 02 25 EC 02 74 9D 02 C2 4F 30 00 10 30 00 10 30 00 10 30 00 10 30 00 10 11 3A D7 11 88 89 11 D7 3A 02 25 EC 02 74 9D 02 C2 4F
					39 01 00 00 00 00 1F E8 20 9D 74 11 3A D7 03 01 10 47 5E EA B1 0E 3A 20 9D 74 11 3A D7 03 01 10 47 5E EA B1 0E 3A
					39 01 00 00 00 00 19 D0 D2 21 23 1F 21 41 00 00 00 52 41 00 00 00 08 00 C4 11 11 9D 9D 06 00 00
					39 01 00 00 00 00 05 2A 00 00 05 9F
					39 01 00 00 14 00 05 2B 00 00 0C 2F
				];
				qcom,mdss-dsi-on-command-state = "dsi_lp_mode";

				qcom,mdss-dsi-post-panel-on-command = [
					05 01 00 00 14 00 01 29
				];

				qcom,mdss-dsi-off-command = [
					39 01 00 00 00 00 03 53 0C 30
					39 01 00 00 00 00 05 CA 08 90 18 05
					05 01 00 00 0A 00 01 28
					05 01 00 00 64 00 01 10
				];
				qcom,mdss-dsi-off-command-state = "dsi_lp_mode";

				iris,abyp-panel-command = [
					07 01 00 00 10 00 02 11 00
					39 01 00 00 11 00 05 2A 00 00 05 9F
					39 01 00 00 11 00 05 2B 00 00 0C 2F
				];
				iris,abyp-panel-command-state = "dsi_lp_mode";

				qcom,mdss-dsi-timing-switch-command = [
					15 00 00 00 00 00 02 B0 AC
					07 00 00 00 00 00 02 31 00
					15 01 00 00 00 00 02 3D 0B
				];
				qcom,mdss-dsi-timing-switch-command-state = "dsi_lp_mode";

				qcom,mode-control-dsi-state = "dsi_lp_mode";
				qcom,mdss-dsi-pps-command-state = "dsi_hs_mode";

				qcom,compression-mode = "dsc";
				qcom,mdss-dsc-version = <0x11>;
				qcom,mdss-dsc-scr-version = <0x1>;
				qcom,mdss-dsc-slice-height = <60>;
				qcom,mdss-dsc-slice-width = <360>;
				qcom,mdss-dsc-slice-per-pkt = <2>;
				qcom,mdss-dsc-bit-per-component = <8>;
				qcom,mdss-dsc-bit-per-pixel = <8>;
				qcom,lm-split = <360 360>;
				qcom,mdss-dsc-encoders = <2>;
				qcom,mdss-dsc-block-prediction-enable;
			};
		};
	};
};

&mdss_dsi1 {
	status = "disabled";
};
